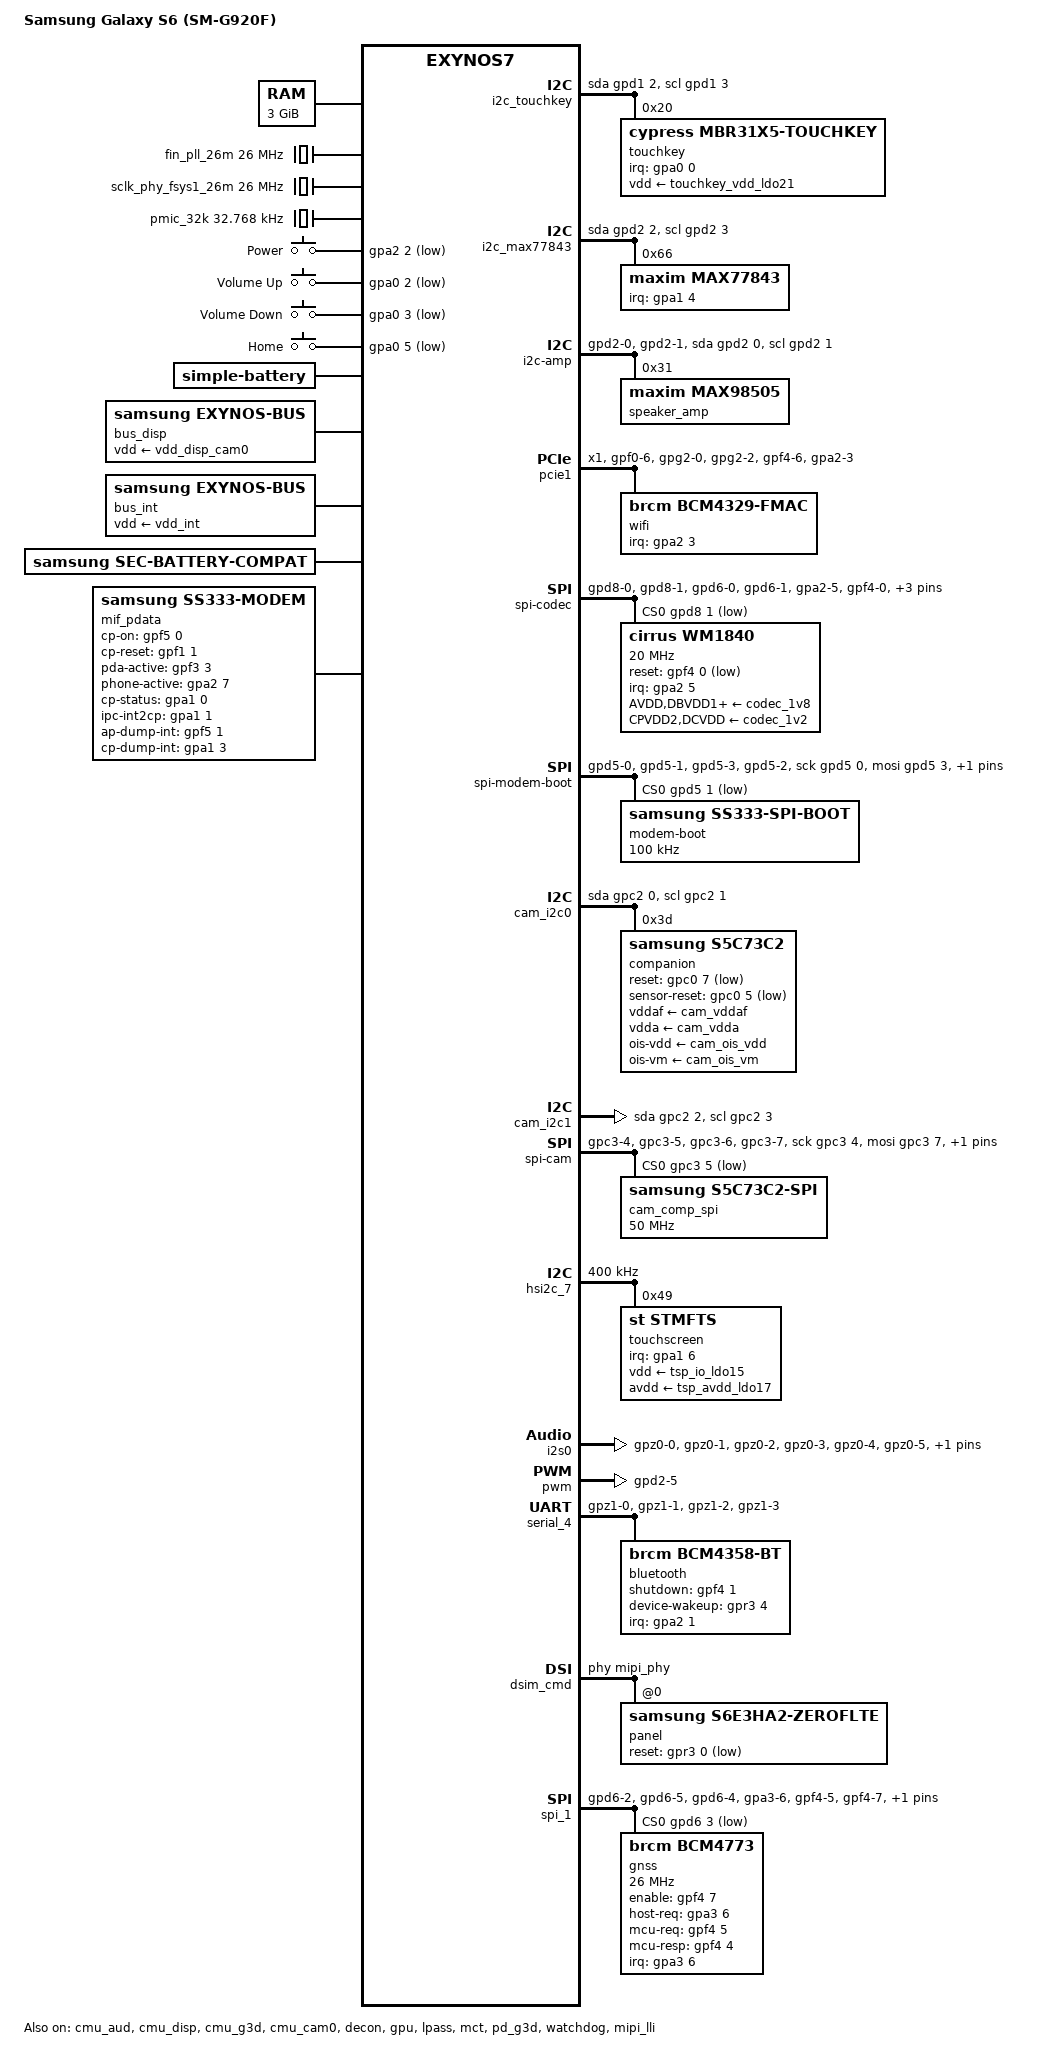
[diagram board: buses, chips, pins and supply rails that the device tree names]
// SPDX-License-Identifier: GPL-2.0
/*
 * Samsung Galaxy S6 (SM-G920F, zeroflte) device tree
 *
 * Exynos 7420, EUR single SIM, board revisions 00 to 07.
 * Hardware facts are taken from the stock 3.10 kernel (exynos7420.dtsi,
 * exynos7420-zero_common.dtsi, exynos7420-zeroflte_eur_open_*.dts).
 */

/dts-v1/;
#include "exynos7.dtsi"
#include <dt-bindings/gpio/gpio.h>
#include <dt-bindings/input/input.h>
#include <dt-bindings/interrupt-controller/irq.h>
#include <dt-bindings/leds/common.h>
#include <dt-bindings/sound/madera.h>
#include "exynos7420-zeroflte-touch-power.dtsi"

/ {
	model = "Samsung Galaxy S6 (SM-G920F)";
	compatible = "samsung,zeroflte", "samsung,exynos7420",
		     "samsung,exynos7";

	/*
	 * S-Boot picks the DTB from the DTBH table by these values. 10-11 is
	 * the EUR rev06 board range (androidboot.hw_rev=11), as in the 3.10
	 * exynos7420-zeroflte_eur_open_06.dts.
	 */
	model_info-chip = <7420>;
	model_info-platform = "android";
	model_info-subtype = "samsung";
	model_info-hw_rev = <10>;
	model_info-hw_rev_end = <11>;

	aliases {
		serial0 = &serial_4;
		/*
		 * Fixed i2c bus numbers, in the order they probe today. Android
		 * sepolicy and HALs name the bus directories (i2c-1 PMIC, i2c-3
		 * MAX77843), so the numbers must not follow probe order.
		 */
		i2c0 = &i2c_touchkey;
		i2c1 = "/i2c-tsp-main-pmic";
		i2c2 = "/i2c-tsp-analog-pmic";
		i2c3 = &i2c_max77843;
		i2c4 = "/i2c-amp";
		i2c5 = &hsi2c_7;
	};

	chosen {
		/*
		 * S-Boot writes bootargs and the initrd range here when it loads
		 * the boot image; the kernel's own arguments are in CONFIG_CMDLINE.
		 */
		#address-cells = <2>;
		#size-cells = <2>;
		ranges;

		/* Left running by S-Boot; DECON takes it over at bind. */
		framebuffer@e2a00000 {
			compatible = "simple-framebuffer";
			reg = <0x0 0xe2a00000 0x0 0x1000000>;
			width = <1440>;
			height = <2560>;
			stride = <(1440 * 4)>;
			format = "a8r8g8b8";
		};
	};

	memory@40000000 {
		device_type = "memory";
		reg = <0x0 0x40000000 0x0 0xc0000000>;
	};

	reserved-memory {
		#address-cells = <2>;
		#size-cells = <2>;
		ranges;

		/* S-Boot debug area */
		sec-debug@40000000 {
			reg = <0x0 0x40000000 0x0 0x10000>;
			no-map;
		};

		/* Exynos-snapshot header and kernel log ring, shared with the
		 * 3.10 kernels: init/dsh_esslog.c writes this boot's log there
		 * for TWRP's /proc/last_kmsg. */
		ess-header@46000000 {
			reg = <0x0 0x46000000 0x0 0x1000>;
			no-map;
		};

		ess-klog@46800000 {
			reg = <0x0 0x46800000 0x0 0x200000>;
			no-map;
		};

		ramoops@46d80000 {
			compatible = "ramoops";
			reg = <0x0 0x46d80000 0x0 0x80000>;
			record-size = <0x10000>;
			console-size = <0x40000>;
			pmsg-size = <0x20000>;
		};

		/* TIMA and AVC logs written by the secure world */
		tima@48002000 {
			reg = <0x0 0x48002000 0x0 0x200000>;
			no-map;
		};

		avc@48204000 {
			reg = <0x0 0x48204000 0x0 0x40000>;
			no-map;
		};

		/*
		 * DECON keeps scanning it out through its SysMMU until the
		 * first frame of its own: map it 1:1 and keep the DMA
		 * allocator off that IOVA range.
		 */
		boot_fb: framebuffer@e2a00000 {
			reg = <0x0 0xe2a00000 0x0 0x1000000>;
			iommu-addresses = <&decon 0xe2a00000 0x1000000>;
			no-map;
		};

		/* Secure world; stock /memreserve/ 0xfe800000 0x1800000 */
		trustzone@fe800000 {
			reg = <0x0 0xfe800000 0x0 0x1800000>;
			no-map;
		};
	};

	/*
	 * Fixed stand-ins for the CMU_TOP1 and PERIC outputs. Those CMUs are
	 * disabled below, so S-Boot's PLL and divider setup stays as is;
	 * the leaf CMUs find these parents by name. CMU_TOPC and CMU_TOP0
	 * are registered since the 2026-11-06 probe and supply the rest.
	 */
	clocks {
		aclk_fsys0_200: clock-aclk-fsys0-200 {
			compatible = "fixed-clock";
			#clock-cells = <0>;
			clock-frequency = <200000000>;
			clock-output-names = "aclk_fsys0_200";
		};

		sclk_mmc2: clock-sclk-mmc2 {
			compatible = "fixed-clock";
			#clock-cells = <0>;
			clock-frequency = <800000000>;
			clock-output-names = "sclk_mmc2";
		};

		sclk_usbdrd300: clock-sclk-usbdrd300 {
			compatible = "fixed-clock";
			#clock-cells = <0>;
			clock-frequency = <50000000>;
			clock-output-names = "sclk_usbdrd300";
		};

		aclk_fsys1_200: clock-aclk-fsys1-200 {
			compatible = "fixed-clock";
			#clock-cells = <0>;
			clock-frequency = <200000000>;
			clock-output-names = "aclk_fsys1_200";
		};

		sclk_mmc0: clock-sclk-mmc0 {
			compatible = "fixed-clock";
			#clock-cells = <0>;
			clock-frequency = <800000000>;
			clock-output-names = "sclk_mmc0";
		};

		sclk_mmc1: clock-sclk-mmc1 {
			compatible = "fixed-clock";
			#clock-cells = <0>;
			clock-frequency = <800000000>;
			clock-output-names = "sclk_mmc1";
		};

		sclk_ufsunipro20: clock-sclk-ufsunipro20 {
			compatible = "fixed-clock";
			#clock-cells = <0>;
			clock-frequency = <166666667>;
			clock-output-names = "sclk_ufsunipro20";
		};

		fin_pll_26m: clock-fin-pll-26m {
			compatible = "fixed-clock";
			#clock-cells = <0>;
			clock-frequency = <26000000>;
			clock-output-names = "fin_pll_26m";
		};

		sclk_phy_fsys1_26m: clock-sclk-phy-fsys1-26m {
			compatible = "fixed-clock";
			#clock-cells = <0>;
			clock-frequency = <26000000>;
			clock-output-names = "sclk_phy_fsys1_26m";
		};

		hsi2c7_clk: clock-hsi2c7 {
			compatible = "fixed-clock";
			#clock-cells = <0>;
			clock-frequency = <133000000>;
			clock-output-names = "hsi2c7_pclk";
		};

		/*
		 * 32.768 kHz from the S2MPS15 into WM1840 MCLK2. The vendor
		 * kernel (noble_arizona) uses it as the 32k and FLL reference
		 * and never gates it; mainline has no S2MPS15 clock driver, so
		 * it is fixed.
		 */
		pmic_32k: clock-pmic-32k {
			compatible = "fixed-clock";
			#clock-cells = <0>;
			clock-frequency = <32768>;
			clock-output-names = "pmic_32khz";
		};
	};

	/*
	 * Interrupt-driven: the alive-block EINTs work on this kernel (the
	 * touchkey IRQ on gpa0 fires). Power and Home wake the system.
	 */
	gpio-keys {
		compatible = "gpio-keys";
		pinctrl-names = "default";
		pinctrl-0 = <&key_power_pins &key_volup_pins &key_voldown_pins
			     &key_home_pins>;

		key-power {
			label = "Power";
			gpios = <&gpa2 2 GPIO_ACTIVE_LOW>;
			linux,code = <KEY_POWER>;
			wakeup-source;
		};

		key-volume-up {
			label = "Volume Up";
			gpios = <&gpa0 2 GPIO_ACTIVE_LOW>;
			linux,code = <KEY_VOLUMEUP>;
		};

		key-volume-down {
			label = "Volume Down";
			gpios = <&gpa0 3 GPIO_ACTIVE_LOW>;
			linux,code = <KEY_VOLUMEDOWN>;
		};

		key-home {
			label = "Home";
			gpios = <&gpa0 5 GPIO_ACTIVE_LOW>;
			linux,code = <KEY_HOMEPAGE>;
			wakeup-source;
		};
	};

	i2c_touchkey: i2c-touchkey {
		compatible = "i2c-gpio";
		sda-gpios = <&gpd1 2 (GPIO_ACTIVE_HIGH | GPIO_OPEN_DRAIN)>;
		scl-gpios = <&gpd1 3 (GPIO_ACTIVE_HIGH | GPIO_OPEN_DRAIN)>;
		i2c-gpio,delay-us = <2>;
		#address-cells = <1>;
		#size-cells = <0>;

		touchkey@20 {
			compatible = "cypress,mbr31x5-touchkey";
			reg = <0x20>;
			interrupt-parent = <&gpa0>;
			interrupts = <0 IRQ_TYPE_EDGE_FALLING>;
			pinctrl-names = "default";
			pinctrl-0 = <&touchkey_irq_pins>;
			linux,keycodes = <KEY_APPSELECT KEY_BACK>;
			vdd-supply = <&touchkey_vdd_ldo21>;
		};
	};

	/*
	 * Charging limits from the stock battery description, the same on
	 * every G920F revision (rev 06-07 boards: exynos7420-zeroflte_eur_
	 * battery_08/09.dtsi): float 4.35 V, fast charge 2 A, top-off
	 * 275 mA, recharge at 4.30 V. Charging stops below 0 degC and from
	 * 50 degC; below 10 degC and from 41 degC (battery swelling) the
	 * charger node's alert limits apply.
	 */
	battery: battery {
		compatible = "simple-battery";
		device-chemistry = "lithium-ion";
		constant-charge-voltage-max-microvolt = <4350000>;
		constant-charge-current-max-microamp = <2000000>;
		charge-term-current-microamp = <275000>;
		re-charge-voltage-microvolt = <4300000>;
		operating-range-celsius = <0 50>;
		alert-celsius = <10 41>;
	};

	/*
	 * Display bus (aclk_disp_400, CMU_TOP0). It has no load counters, so
	 * it runs at the lowest OPP the DECON's bandwidth request allows:
	 * 100 MHz while no frame is sent, up to 267 MHz, the stock cap, for
	 * two full-screen windows.
	 *
	 * Rates are divisions of the 800 MHz BUS0 PLL mux that S-Boot
	 * selects. 650 mV is the stock CAM/DISP ASV table v15 entry for
	 * 100-267 MHz at this chip's fused group (cam_disp_asv_group 0x999,
	 * ASV9, from the 3.10 boot log); stock ran these levels at that
	 * voltage, plus 37.5 mV only when the TMU reported the chip cold,
	 * which nothing here does. The upper limit of 1 V leaves room for the
	 * camera ISP, which shares BUCK5. G925F needs its own values.
	 */
	bus_disp: bus-disp {
		compatible = "samsung,exynos-bus";
		clocks = <&clock_top0 CLK_DOUT_ACLK_DISP_400>;
		clock-names = "bus";
		vdd-supply = <&vdd_disp_cam0>;
		operating-points-v2 = <&bus_disp_opp_table>;
		#interconnect-cells = <0>;
		/* display traffic also sets a DRAM floor */
		interconnects = <&dmc>;
	};

	bus_disp_opp_table: opp-table-bus-disp {
		compatible = "operating-points-v2";

		opp-100000000 {
			opp-hz = /bits/ 64 <100000000>;
			opp-microvolt = <650000 650000 1000000>;
		};
		opp-160000000 {
			opp-hz = /bits/ 64 <160000000>;
			opp-microvolt = <650000 650000 1000000>;
		};
		opp-200000000 {
			opp-hz = /bits/ 64 <200000000>;
			opp-microvolt = <650000 650000 1000000>;
		};
		opp-266666667 {
			opp-hz = /bits/ 64 <266666667>;
			opp-microvolt = <650000 650000 1000000>;
		};
	};

	/*
	 * Internal bus (INT, BUCK4), as on Exynos 5433 TM2: bus0 is the parent,
	 * driven by the general-port PPMUs of the four DREX channels (the
	 * non-CPU traffic; stock used the same counters for INT), and the other
	 * INT clocks follow it by OPP index.
	 *
	 * Every rate divides the 400 MHz bus0 PLL half that S-Boot selects
	 * (1600 MHz / 4); the muxes never change. 400 MHz is S-Boot's level and
	 * stock INT_LV7, 200 and 100 MHz are LV10 and LV11, with the same child
	 * clocks as stock. Voltages are the stock INT ASV table v15 entries for
	 * this chip's group (int_asv_group 0x999, ASV9): 712.5 mV for 400 MHz,
	 * 650 mV below. Stock's 532/560 MHz levels need 793.75 mV and another
	 * PLL; they are left out. MFC, MSCL, VPP and the other INT clocks keep
	 * their S-Boot rates. G925F needs its own values.
	 */
	bus_int: bus-int {
		compatible = "samsung,exynos-bus";
		clocks = <&clock_topc DOUT_ACLK_BUS0_532>;
		clock-names = "bus";
		devfreq-events = <&ppmu_event0_d0_general>,
				 <&ppmu_event0_d1_general>,
				 <&ppmu_event0_d2_general>,
				 <&ppmu_event0_d3_general>;
		vdd-supply = <&vdd_int>;
		exynos,saturation-ratio = <10>;
		operating-points-v2 = <&bus_int_opp_table>;
	};

	bus_int_opp_table: opp-table-bus-int {
		compatible = "operating-points-v2";

		opp-100000000 {
			opp-hz = /bits/ 64 <100000000>;
			opp-microvolt = <650000 650000 1000000>;
		};
		opp-200000000 {
			opp-hz = /bits/ 64 <200000000>;
			opp-microvolt = <650000 650000 1000000>;
		};
		opp-400000000 {
			opp-hz = /bits/ 64 <400000000>;
			opp-microvolt = <712500 712500 1000000>;
		};
	};

	bus_int_bus1: bus-int-bus1 {
		compatible = "samsung,exynos-bus";
		clocks = <&clock_topc DOUT_ACLK_BUS1_532>;
		clock-names = "bus";
		devfreq = <&bus_int>;
		operating-points-v2 = <&bus_int_bus1_opp_table>;
	};

	bus_int_bus1_opp_table: opp-table-bus-int-bus1 {
		compatible = "operating-points-v2";

		opp-100000000 {
			opp-hz = /bits/ 64 <100000000>;
		};
		opp-200000000 {
			opp-hz = /bits/ 64 <200000000>;
		};
		opp-400000000 {
			opp-hz = /bits/ 64 <400000000>;
		};
	};

	bus_int_bus1_200: bus-int-bus1-200 {
		compatible = "samsung,exynos-bus";
		clocks = <&clock_topc DOUT_ACLK_BUS1_200>;
		clock-names = "bus";
		devfreq = <&bus_int>;
		operating-points-v2 = <&bus_int_bus1_200_opp_table>;
	};

	bus_int_bus1_200_opp_table: opp-table-bus-int-bus1-200 {
		compatible = "operating-points-v2";

		opp-80000000 {
			opp-hz = /bits/ 64 <80000000>;
		};
		opp-100000000 {
			opp-hz = /bits/ 64 <100000000>;
		};
		opp-200000000 {
			opp-hz = /bits/ 64 <200000000>;
		};
	};

	bus_int_imem: bus-int-imem {
		compatible = "samsung,exynos-bus";
		clocks = <&clock_topc DOUT_ACLK_IMEM_266>;
		clock-names = "bus";
		devfreq = <&bus_int>;
		operating-points-v2 = <&bus_int_imem_opp_table>;
	};

	bus_int_imem_opp_table: opp-table-bus-int-imem {
		compatible = "operating-points-v2";

		opp-80000000 {
			opp-hz = /bits/ 64 <80000000>;
		};
		opp-100000000 {
			opp-hz = /bits/ 64 <100000000>;
		};
		opp-200000000 {
			opp-hz = /bits/ 64 <200000000>;
		};
	};

	bus_int_pclk: bus-int-pclk {
		compatible = "samsung,exynos-bus";
		clocks = <&clock_topc DOUT_PCLK_BUS01_133>;
		clock-names = "bus";
		devfreq = <&bus_int>;
		operating-points-v2 = <&bus_int_pclk_opp_table>;
	};

	bus_int_pclk_opp_table: opp-table-bus-int-pclk {
		compatible = "operating-points-v2";

		opp-25000000 {
			opp-hz = /bits/ 64 <25000000>;
		};
		opp-50000000 {
			opp-hz = /bits/ 64 <50000000>;
		};
		opp-100000000 {
			opp-hz = /bits/ 64 <100000000>;
		};
	};

	dmc_opp_table: opp-table-dmc {
		compatible = "operating-points-v2";
		opp-133000000 {
			opp-hz = /bits/ 64 <133000000>;
			opp-microvolt = <587500>;
		};
		opp-167000000 {
			opp-hz = /bits/ 64 <167000000>;
			opp-microvolt = <587500>;
		};
		opp-259000000 {
			opp-hz = /bits/ 64 <259000000>;
			opp-microvolt = <587500>;
		};
		opp-348000000 {
			opp-hz = /bits/ 64 <348000000>;
			opp-microvolt = <587500>;
		};
		opp-418000000 {
			opp-hz = /bits/ 64 <418000000>;
			opp-microvolt = <587500>;
		};
		opp-543000000 {
			opp-hz = /bits/ 64 <543000000>;
			opp-microvolt = <656250>;
		};
		opp-635000000 {
			opp-hz = /bits/ 64 <635000000>;
			opp-microvolt = <668750>;
		};
		opp-836000000 {
			opp-hz = /bits/ 64 <836000000>;
			opp-microvolt = <712500>;
		};
		opp-1026000000 {
			opp-hz = /bits/ 64 <1026000000>;
			opp-microvolt = <731250>;
		};
		opp-1264000000 {
			opp-hz = /bits/ 64 <1264000000>;
			opp-microvolt = <756250>;
		};
		opp-1464000000 {
			opp-hz = /bits/ 64 <1464000000>;
			opp-microvolt = <787500>;
		};
		opp-1552000000 {
			opp-hz = /bits/ 64 <1552000000>;
			opp-microvolt = <825000>;
			/* stock suspended on LV0 */
			opp-suspend;
		};
	};

	/* Bus for the MAX77843 MUIC/charger/fuel gauge (stock hsi2c_1 pins) */
	i2c_max77843: i2c-max77843 {
		compatible = "i2c-gpio";
		sda-gpios = <&gpd2 2 (GPIO_ACTIVE_HIGH | GPIO_OPEN_DRAIN)>;
		scl-gpios = <&gpd2 3 (GPIO_ACTIVE_HIGH | GPIO_OPEN_DRAIN)>;
		i2c-gpio,delay-us = <2>;
		#address-cells = <1>;
		#size-cells = <0>;

		/*
		 * TOPSYS: the MFD core. It creates the charger (0x69), fuel
		 * gauge (0x36) and MUIC (0x25) clients for its cells and carries
		 * the haptic block. INTB is level low and shared: each driver
		 * unmasks its block's source only once it handles it, and the
		 * fuel gauge, which is polled, stays masked.
		 */
		max77843: pmic@66 {
			compatible = "maxim,max77843";
			reg = <0x66>;
			interrupt-parent = <&gpa1>;
			interrupts = <4 IRQ_TYPE_LEVEL_LOW>;
			pinctrl-names = "default";
			pinctrl-0 = <&max77843_irq>;

			fuelgauge {
				compatible = "maxim,max77843-fuelgauge";
			};

			/*
			 * The input limit follows the charger type the MUIC
			 * detects. The alert limits are stock's swelling
			 * current and float voltage.
			 */
			charger {
				compatible = "maxim,max77843-charger";
				monitored-battery = <&battery>;
				extcon = <&muic>;
				maxim,alert-charge-current-microamp = <1100000>;
				maxim,alert-charge-voltage-microvolt = <4150000>;
			};

			/*
			 * MUIC: accessory detection and the micro-USB switch,
			 * which routes D+/D- to the USB PHY when a USB host or
			 * charger is attached and opens it on detach.
			 */
			muic: extcon {
				compatible = "maxim,max77843-muic";

				connector {
					compatible = "usb-b-connector";
					label = "micro-USB";
					type = "micro";
				};
			};

			/* LRA motor; the 3.10 G920F period is 33510 ns on PWM timer 1 */
			haptic {
				compatible = "maxim,max77843-haptic";
				haptic-supply = <&vcc_motor>;
				pwms = <&pwm 1 33510 0>;
				pwm-names = "haptic";
			};

			/*
			 * RGB indicator. R, G and B are channels 1-3; channel 0
			 * is not fitted on the S6. The full-scale codes are the
			 * 3.10 zeroflte calibration for the black panel
			 * (normal current 10 times br_ratio 450/200/500 %).
			 */
			led-controller {
				compatible = "maxim,max77843-led";

				multi-led {
					color = <LED_COLOR_ID_RGB>;
					function = LED_FUNCTION_STATUS;
					#address-cells = <1>;
					#size-cells = <0>;

					led@1 {
						reg = <1>;
						color = <LED_COLOR_ID_RED>;
						maxim,brt-code-max = <45>;
					};

					led@2 {
						reg = <2>;
						color = <LED_COLOR_ID_GREEN>;
						maxim,brt-code-max = <20>;
					};

					led@3 {
						reg = <3>;
						color = <LED_COLOR_ID_BLUE>;
						maxim,brt-code-max = <50>;
					};
				};
			};
		};
	};

	/*
	 * The loudspeaker amp sits on HSI2C0 (0x13640000). Its clock is in
	 * CMU_PERIC0, which this board leaves disabled, so the bus is
	 * bit-banged on the same pins, as for the MAX77843. The amp has no
	 * reset or enable line and no switched supply. Its IRQ (gpa2-0) is
	 * unused, as on stock.
	 */
	i2c-amp {
		compatible = "i2c-gpio";
		sda-gpios = <&gpd2 0 (GPIO_ACTIVE_HIGH | GPIO_OPEN_DRAIN)>;
		scl-gpios = <&gpd2 1 (GPIO_ACTIVE_HIGH | GPIO_OPEN_DRAIN)>;
		i2c-gpio,delay-us = <5>;
		i2c-gpio,timeout-ms = <100>;
		pinctrl-names = "default";
		pinctrl-0 = <&amp_i2c>;
		#address-cells = <1>;
		#size-cells = <0>;

		/*
		 * MAX98505, on the WM1840's AIF4. It returns voltage and
		 * current sense on its DOUT, in the stock slots.
		 */
		speaker_amp: audio-codec@31 {
			compatible = "maxim,max98505";
			reg = <0x31>;
			#sound-dai-cells = <0>;
			vmon-slot-no = <2>;
			imon-slot-no = <0>;
		};
	};

	/* PCIe channel 1, BCM4358 Wi-Fi */
	pcie1: pcie@157b0000 {
		compatible = "samsung,exynos7420-pcie";
		reg = <0x0 0x157b0000 0x0 0x1000>,
		      <0x0 0x15660000 0x0 0x1000>,
		      <0x0 0x15630000 0x0 0x1000>,
		      <0x0 0x1005265c 0x0 0x4>,
		      <0x0 0x105c071c 0x0 0x4>,
		      <0x0 0x156e0f00 0x0 0x4>,
		      <0x0 0x156f00e4 0x0 0x4>,
		      <0x0 0x156e0000 0x0 0xd00>,
		      <0x0 0x1c000000 0x0 0x1000>;
		reg-names = "dbi", "elbi", "phy", "block", "pmu", "cmu",
			    "phy_pcs", "gates", "config";
		interrupts = <GIC_SPI 205 IRQ_TYPE_LEVEL_HIGH>;
		#address-cells = <3>;
		#size-cells = <2>;
		device_type = "pci";
		ranges = <0x82000000 0x0 0x1c011000 0x0 0x1c011000 0x0 0x3feefff>;
		dma-ranges = <0x42000000 0x0 0x0 0x0 0x0 0x1 0x0>;
		bus-range = <0x00 0xff>;
		num-lanes = <1>;
		perst-gpios = <&gpg2 0 GPIO_ACTIVE_LOW>;
		wl-en-gpios = <&gpf4 6 GPIO_ACTIVE_HIGH>;
		pinctrl-names = "default", "pcie_reset";
		pinctrl-0 = <&pcie1_clkreq &pcie1_perst &pcie1_reset_clear
			     &cfg_wlanen &wlan_host_wake>;
		pinctrl-1 = <&pcie1_clkreq &pcie1_perst &pcie1_reset
			     &cfg_wlanen &wlan_host_wake>;

		/* Root port 00:00.0 */
		pcie@0,0 {
			device_type = "pci";
			reg = <0x0000 0x0 0x0 0x0 0x0>;
			#address-cells = <3>;
			#size-cells = <2>;
			ranges;

			/*
			 * BCM4358 at 01:00.0. brcmfmac arms WLAN_HOST_WAKE as
			 * its wake IRQ, so the link can stay associated while
			 * the host sleeps.
			 */
			wifi@0,0 {
				compatible = "brcm,bcm4329-fmac";
				reg = <0x10000 0x0 0x0 0x0 0x0>;
				interrupt-parent = <&gpa2>;
				interrupts = <3 IRQ_TYPE_EDGE_RISING>;
				interrupt-names = "host-wake";
				/*
				 * ISO 3166 to firmware ccode/rev, from Samsung's
				 * bcmdhd4358 translate_custom_table. Without it
				 * brcmfmac ignores the country Android sets on a
				 * BCM4358 and the firmware keeps its NVRAM default.
				 */
				brcm,ccode-map = "IR-XZ-11", "SD-XZ-11", "SY-XZ-11", "PS-XZ-11", "TL-XZ-11",
						"MH-XZ-11", "GL-GP-2", "AL-AL-2", "AS-AS-12", "AI-AI-1",
						"AF-AD-0", "AG-AG-2", "AM-AM-1", "AR-AU-6", "AW-AW-2",
						"AU-AU-6", "AT-AT-4", "AZ-AZ-2", "BS-BS-2", "BH-BH-4",
						"BD-BD-1", "BY-BY-3", "BE-BE-4", "BM-BM-12", "BA-BA-2",
						"BR-BR-2", "VG-VG-2", "BN-BN-4", "BG-BG-4", "KH-KH-2",
						"KY-KY-3", "CN-CN-38", "CO-CO-17", "CR-CR-17", "HR-HR-4",
						"CY-CY-4", "CZ-CZ-4", "DK-DK-4", "EE-EE-4", "ET-ET-2",
						"FI-FI-4", "FR-FR-5", "GF-GF-2", "DE-DE-7", "GR-GR-4",
						"GD-GD-2", "GP-GP-2", "GU-GU-30", "HK-HK-2", "HU-HU-4",
						"IS-IS-4", "IN-IN-3", "ID-ID-1", "IE-IE-5", "IL-IL-14",
						"IT-IT-4", "JP-JP-968", "JO-JO-3", "KE-SA-0", "KW-KW-5",
						"LA-LA-2", "LV-LV-4", "LB-LB-5", "LS-LS-2", "LI-LI-4",
						"LT-LT-4", "LU-LU-3", "MO-SG-0", "MK-MK-2", "MW-MW-1",
						"MY-MY-19", "DZ-DZ-2", "TW-TW-65", "MV-MV-3", "MT-MT-4",
						"MQ-MQ-2", "MR-MR-2", "MU-MU-2", "YT-YT-2", "MX-MX-44",
						"MD-MD-2", "MC-MC-1", "ME-ME-2", "MA-MA-2", "NL-NL-4",
						"AN-GD-2", "NZ-NZ-4", "NO-NO-4", "OM-OM-4", "PA-PA-17",
						"PG-AU-6", "PY-PY-2", "PE-PE-20", "PH-PH-5", "PL-PL-4",
						"PT-PT-4", "PR-PR-38", "RE-RE-2", "RO-RO-4", "SN-MA-2",
						"RS-RS-2", "SK-SK-4", "SI-SI-4", "ES-ES-4", "LK-LK-1",
						"SE-SE-4", "CH-CH-4", "TH-TH-5", "TT-TT-3", "TR-TR-7",
						"AE-AE-6", "GB-GB-6", "UY-VE-3", "VI-PR-38", "VA-VA-2",
						"VE-VE-3", "VN-VN-4", "ZM-LA-2", "EC-EC-21", "SV-SV-25",
						"KR-KR-70", "RU-RU-986", "UA-UA-16", "GT-GT-1", "MN-MN-1",
						"NI-NI-2", "UZ-MA-2", "ZA-ZA-19", "EG-EG-13", "TN-TN-1",
						"AO-AD-0", "BT-BJ-0", "BW-BJ-0", "LY-LI-4", "BO-NG-0",
						"UM-PR-38", "US-US-988", "CU-US-988", "CA-Q2-993";
			};
		};
	};

	sound {
		compatible = "samsung,zero-wm1840";
		model = "zero-wm1840";
		samsung,i2s-controller = <&i2s0>;
		samsung,speaker-amp = <&speaker_amp>;
		samsung,audio-routing =
			"HP", "HPOUT1L",
			"HP", "HPOUT1R",
			"RCV", "HPOUT3L",
			"RCV", "HPOUT3R",
			"SPK", "BE_OUT",
			"IN1ALN", "Main Mic",
			"IN1RN", "Main Mic",
			"Main Mic", "MICBIAS1",
			"IN2BLN", "Headset Mic",
			"IN2BLP", "Headset Mic",
			"Headset Mic", "MICBIAS2",
			"IN3LN", "Sub Mic",
			"IN3RN", "Sub Mic",
			"Sub Mic", "MICBIAS4",
			"DMICCLK4", "Third Mic",
			"DMICDAT4", "Third Mic",
			"Third Mic", "MICBIAS3";
	};

	/*
	 * Audio: Cirrus Logic WM1840 (Madera, CS47L85 family) on AIF1 <-> I2S0.
	 * Board facts are from the stock rev01-07 DT; only rev00 had a WM5110.
	 *
	 * The codec sits on SPI0's pins, but the SPI0 controller is clocked
	 * from CMU_PERIC1, which hangs the bus on this board, so the bus is
	 * bit-banged on the same pins in pinctrl_bus0 (CLK gpd8-0, CS gpd8-1,
	 * MISO gpd6-0, MOSI gpd6-1). IRQ is gpa2-5 (active low), reset gpf4-0.
	 *
	 * The codec's FLL1 runs from MCLK2, the PMIC's 32.768 kHz output,
	 * which S-Boot leaves running (the BCM4358 uses it too); pmic_32k
	 * stands in for it.
	 */
	spi-codec {
		compatible = "spi-gpio";
		#address-cells = <1>;
		#size-cells = <0>;
		sck-gpios = <&gpd8 0 GPIO_ACTIVE_HIGH>;
		miso-gpios = <&gpd6 0 GPIO_ACTIVE_HIGH>;
		mosi-gpios = <&gpd6 1 GPIO_ACTIVE_HIGH>;
		cs-gpios = <&gpd8 1 GPIO_ACTIVE_LOW>;
		num-chipselects = <1>;
		/*
		 * The SoC pins for the codec are set here: the codec node's
		 * own pinctrl-0 is taken by its internal pin-settings.
		 */
		pinctrl-names = "default";
		pinctrl-0 = <&codec_spi &codec_irq &codec_reset>;

		wm1840: codec@0 {
			compatible = "cirrus,wm1840";
			reg = <0>;
			spi-max-frequency = <20000000>;

			interrupt-parent = <&gpa2>;
			interrupts = <5 IRQ_TYPE_LEVEL_LOW>;
			interrupt-controller;
			#interrupt-cells = <2>;
			gpio-controller;
			#gpio-cells = <2>;
			reset-gpios = <&gpf4 0 GPIO_ACTIVE_LOW>;

			clocks = <&pmic_32k>;
			clock-names = "mclk2";

			AVDD-supply = <&codec_1v8>;
			DBVDD1-supply = <&codec_1v8>;
			DBVDD2-supply = <&codec_1v8>;
			DBVDD3-supply = <&codec_1v8>;
			DBVDD4-supply = <&codec_1v8>;
			CPVDD1-supply = <&codec_1v8>;
			CPVDD2-supply = <&codec_1v2>;
			DCVDD-supply = <&codec_1v2>;
			SPKVDDL-supply = <&codec_1v8>;
			SPKVDDR-supply = <&codec_1v8>;

			/*
			 * IN1 (main), IN3 (sub) and IN4 (third) are DMICs.
			 * cirrus,inmode only takes DIFF or SE: IN1 and IN3 are
			 * switched to DMIC with the "IN1 Mode"/"IN3 Mode"
			 * controls, IN4 is digital only. IN2B, the headset
			 * mic, is differential, the default.
			 */
			cirrus,dmic-ref = <MADERA_DMIC_REF_MICBIAS1
					   MADERA_DMIC_REF_MICBIAS2
					   MADERA_DMIC_REF_MICBIAS1
					   MADERA_DMIC_REF_MICVDD
					   MADERA_DMIC_REF_MICVDD
					   MADERA_DMIC_REF_MICVDD>;
			/* OUT2 and OUT3 (earpiece) are mono. */
			cirrus,out-mono = <0 1 1 0 0 0>;
			cirrus,max-channels-clocked = <2 0 0 0>;

			pinctrl-names = "default";
			pinctrl-0 = <&wm1840_pins>;

			wm1840_pins: pin-settings {
				aif1-pins {
					groups = "aif1";
					function = "aif1";
					bias-bus-hold;
				};

				aif2-pins {
					groups = "aif2";
					function = "aif2";
					bias-bus-hold;
				};

				aif3-pins {
					groups = "aif3";
					function = "aif3";
					bias-bus-hold;
				};

				aif4-pins {
					groups = "aif4";
					function = "aif4";
					bias-bus-hold;
				};
			};
		};
	};
};

/*
 * The clusters run from the alternate input while their PLL relocks. Its
 * BUS0_PLL side comes through CMU_TOPC. That was unreadable when this was
 * written and is registered now, but the 24 MHz oscillator stays the
 * alternate input: a known rate for the few tens of microseconds a relock
 * takes, independent of any TOPC setting.
 */
&clock_atlas {
	assigned-clocks = <&clock_atlas CLK_MOUT_BUS0_PLL_ATLAS_USER>;
	assigned-clock-parents = <&fin_pll>;
};

&clock_apollo {
	assigned-clocks = <&clock_apollo CLK_MOUT_BUS0_PLL_APOLLO_USER>;
	assigned-clock-parents = <&fin_pll>;
};

&cpu_atlas0 {
	cpu-supply = <&vdd_atlas>;
};

&cpu_atlas1 {
	cpu-supply = <&vdd_atlas>;
};

&cpu_atlas2 {
	cpu-supply = <&vdd_atlas>;
};

&cpu_atlas3 {
	cpu-supply = <&vdd_atlas>;
};

&cpu_apollo0 {
	cpu-supply = <&vdd_apollo>;
};

&cpu_apollo1 {
	cpu-supply = <&vdd_apollo>;
};

&cpu_apollo2 {
	cpu-supply = <&vdd_apollo>;
};

&cpu_apollo3 {
	cpu-supply = <&vdd_apollo>;
};

/* Leave the S-Boot root clock setup alone; see the stand-ins above. */
/*
 * CMU_TOPC and CMU_TOP0 are registered: every register their drivers use
 * reads and writes from Linux (2026-11-06 probe). Only undefined offsets
 * abort, such as TOP0 +0x0 and TOPC +0x80c; the early "TOP0 hangs" came
 * from a probe of TOP0's base. TOP1, CCORE, PERIC0 and PERIC1 stay off.
 */
&clock_top1 {
	status = "disabled";
};

&clock_ccore {
	status = "disabled";
};

&clock_peric0 {
	status = "disabled";
};

&clock_peric1 {
	status = "disabled";
};

&clock_fsys0 {
	clocks = <&fin_pll>, <&aclk_fsys0_200>, <&sclk_mmc2>;
};

&clock_fsys1 {
	/* fin_pll_26m stands in for dout_sclk_phy_fsys1 (not used by name). */
	clocks = <&fin_pll>, <&aclk_fsys1_200>, <&sclk_mmc0>, <&sclk_mmc1>,
		 <&sclk_ufsunipro20>, <&fin_pll_26m>, <&sclk_phy_fsys1_26m>;
};

&cmu_aud {
	status = "okay";
};

/*
 * CMU_DISP's parents come from CMU_TOP0 (aclk_disp_400, decon eclk and
 * vclk), which is registered, so the rates are the real S-Boot settings.
 */
&cmu_disp {
	status = "okay";
};

&cmu_g3d {
	status = "okay";
};

/*
 * CMU_CAM0 feeds the CSIS0 -> FIMC-BNS A (rear) and CSIS1 -> FIMC-BNS B
 * (front) capture paths. Its user muxes come up on OSCCLK with the power
 * domain; move them to the CMU_TOP0 bus clocks and the D-PHY byte clocks
 * (stock does the same when the ISP powers on, before any PHY runs), and
 * set the APB dividers to the stock sensor-on rates. The CMU_TOP0 parents
 * stay as S-Boot leaves them.
 */
&cmu_cam0 {
	assigned-clocks = <&cmu_cam0 CLK_MOUT_USER_ACLK_CAM0_CSIS0_690>,
			  <&cmu_cam0 CLK_MOUT_USER_ACLK_CAM0_BNSA_690>,
			  <&cmu_cam0 CLK_MOUT_USER_ACLK_CAM0_TREX_532>,
			  <&cmu_cam0 CLK_MOUT_USER_ACLK_CAM0_NOCP_133>,
			  <&cmu_cam0 CLK_MOUT_USER_ACLK_CAM0_CSIS1_174>,
			  <&cmu_cam0 CLK_MOUT_USER_ACLK_CAM0_BNSB_690>,
			  <&cmu_cam0 CLK_MOUT_USER_PHYCLK_RXBYTECLKHS0_S2A>,
			  <&cmu_cam0 CLK_MOUT_USER_PHYCLK_RXBYTECLKHS0_S4>,
			  <&cmu_cam0 CLK_MOUT_USER_PHYCLK_RXBYTECLKHS1_S4>,
			  <&cmu_cam0 CLK_MOUT_USER_PHYCLK_RXBYTECLKHS2_S4>,
			  <&cmu_cam0 CLK_MOUT_USER_PHYCLK_RXBYTECLKHS3_S4>,
			  <&cmu_cam0 CLK_DOUT_PCLK_CAM0_BNSA_345>,
			  <&cmu_cam0 CLK_DOUT_PCLK_CAM0_BNSB_345>,
			  <&cmu_cam0 CLK_DOUT_PCLK_CAM0_TREX_266>,
			  <&cmu_cam0 CLK_DOUT_PCLK_CAM0_TREX_133>;
	assigned-clock-parents = <&clock_top0 CLK_ACLK_CAM0_CSIS0_690>,
				 <&clock_top0 CLK_ACLK_CAM0_BNSA_690>,
				 <&clock_top0 CLK_ACLK_CAM0_TREX_532>,
				 <&clock_top0 CLK_ACLK_CAM0_NOCP_133>,
				 <&clock_top0 CLK_ACLK_CAM0_CSIS1_174>,
				 <&clock_top0 CLK_ACLK_CAM0_BNSB_690>,
				 <&cmu_cam0 CLK_PHY_RXBYTECLKHS0_S2A>,
				 <&cmu_cam0 CLK_PHY_RXBYTECLKHS0_S4>,
				 <&cmu_cam0 CLK_PHY_RXBYTECLKHS1_S4>,
				 <&cmu_cam0 CLK_PHY_RXBYTECLKHS2_S4>,
				 <&cmu_cam0 CLK_PHY_RXBYTECLKHS3_S4>;
	assigned-clock-rates = <0>, <0>, <0>, <0>, <0>, <0>,
			       <0>, <0>, <0>, <0>, <0>,
			       <330000000>, <330000000>, <266000000>,
			       <133000000>;
	status = "okay";
};

/*
 * The safe DRAM envelope from the CPU clock: stock's cpufreq bus tables
 * never ran MIF under 543 MHz with an A57 at 1 GHz or more or an A53 at
 * 700 MHz or more, and the deep levels under fast CPUs hang the SoC
 * (test-182/183/185). The OPP core sets this vote before the clock
 * rises, so it holds only that first step (543 MHz x 16 bytes); the
 * higher stock steps come from memlat in the dmc, for cores that wait on
 * DRAM. The vote changes only when a cluster crosses that clock.
 */
&cpu_atlas0 {
	interconnects = <&dmc &dmc>;
};

&cpu_atlas1 {
	interconnects = <&dmc &dmc>;
};

&cpu_atlas2 {
	interconnects = <&dmc &dmc>;
};

&cpu_atlas3 {
	interconnects = <&dmc &dmc>;
};

&cpu_apollo0 {
	interconnects = <&dmc &dmc>;
};

&cpu_apollo1 {
	interconnects = <&dmc &dmc>;
};

&cpu_apollo2 {
	interconnects = <&dmc &dmc>;
};

&cpu_apollo3 {
	interconnects = <&dmc &dmc>;
};

&cpu_atlas_opp_table {
	opp-800000000 {
		opp-peak-kBps = <0>;
	};
	opp-900000000 {
		opp-peak-kBps = <0>;
	};
	opp-1000000000 {
		opp-peak-kBps = <8688000>;
	};
	opp-1100000000 {
		opp-peak-kBps = <8688000>;
	};
	opp-1200000000 {
		opp-peak-kBps = <8688000>;
	};
	opp-1300000000 {
		opp-peak-kBps = <8688000>;
	};
	opp-1400000000 {
		opp-peak-kBps = <8688000>;
	};
	opp-1500000000 {
		opp-peak-kBps = <8688000>;
	};
	opp-1600000000 {
		opp-peak-kBps = <8688000>;
	};
	opp-1704000000 {
		opp-peak-kBps = <8688000>;
	};
	opp-1800000000 {
		opp-peak-kBps = <8688000>;
	};
};

&cpu_apollo_opp_table {
	opp-400000000 {
		opp-peak-kBps = <0>;
	};
	opp-500000000 {
		opp-peak-kBps = <0>;
	};
	opp-600000000 {
		opp-peak-kBps = <0>;
	};
	opp-700000000 {
		opp-peak-kBps = <8688000>;
	};
	opp-800000000 {
		opp-peak-kBps = <8688000>;
	};
	opp-900000000 {
		opp-peak-kBps = <8688000>;
	};
	opp-1000000000 {
		opp-peak-kBps = <8688000>;
	};
	opp-1104000000 {
		opp-peak-kBps = <8688000>;
	};
	opp-1200000000 {
		opp-peak-kBps = <8688000>;
	};
	opp-1296000000 {
		opp-peak-kBps = <8688000>;
	};
	opp-1400000000 {
		opp-peak-kBps = <8688000>;
	};
	opp-1500000000 {
		opp-peak-kBps = <8688000>;
	};
};

&decon {
	status = "okay";
	interconnects = <&bus_disp &dmc>;
	/*
	 * Only S-Boot sets up the DSI link and panel; keep the display
	 * running through system sleep.
	 */
	samsung,bootloader-display;
	samsung,disp-sysreg = <&sysreg_system_controller>;
	memory-region = <&boot_fb>;

	/*
	 * The panel's tearing-effect output on GPG0-0, an EINT (3.10:
	 * decon_fb gpios = <&gpg0 0 0xf>, used to time each frame's
	 * software trigger). DECON sends every frame at a TE edge.
	 */
	te-gpios = <&gpg0 0 GPIO_ACTIVE_HIGH>;

	/* Command-mode (i80) MIPI panel, S6E3HA2 */
	i80-if-timings {
	};

	display-timings {
		native-mode = <&decon_timing0>;

		decon_timing0: timing-0 {
			clock-frequency = <221042000>;
			hactive = <1440>;
			vactive = <2560>;
			hfront-porch = <1>;
			hback-porch = <1>;
			hsync-len = <1>;
			vfront-porch = <1>;
			vback-porch = <15>;
			vsync-len = <1>;
		};
	};
};

&fin_pll {
	clock-frequency = <24000000>;
};

&gpu {
	status = "okay";

	/*
	 * The GPU is not attached to pd_g3d. pd_g3d stays powered on its
	 * own: its samsung,exynos7420-g3d-pd compatible makes
	 * exynos-pm-domains set GENPD_FLAG_ALWAYS_ON, and pd_ignore_unused
	 * on the cmdline keeps unused domains on as well. The generic 5433
	 * power-on sequence cannot bring G3D back (the vendor sequence also
	 * writes CMU_TOP registers that hang this board), so the domain
	 * must never power off.
	 *
	 * History: with power-domains attached and no always-on flag,
	 * panfrost's 50 ms autosuspend let genpd power pd_g3d off; the next
	 * runtime resume read 0x14AC0000 and took an asynchronous SError
	 * (p207). With the always-on flag, keeping the property should be
	 * safe too (the p211 plan), but the board runs without it (the p210
	 * fallback) and no p211 boot is recorded. Panfrost runtime PM only
	 * powers the GPU cores on and off.
	 */
	/delete-property/ power-domains;

	/*
	 * GPU DVFS through panfrost devfreq (simple_ondemand). Levels are
	 * the 3.10 G3D_PLL table up to its 700 MHz limit
	 * (GPU_MAX_CLOCK_LIMIT); 772 MHz is left out until 700 MHz has run
	 * stable. Voltages are the ASV group 0 (worst chip) column of the
	 * 3.10 G3D ASV tables v12/v15, so they hold for any ASV group.
	 */
	mali-supply = <&vdd_g3d>;
	operating-points-v2 = <&gpu_opp_table>;

	gpu_opp_table: opp-table {
		compatible = "operating-points-v2";

		opp-266000000 {
			opp-hz = /bits/ 64 <266000000>;
			opp-microvolt = <762500>;
		};

		opp-350000000 {
			opp-hz = /bits/ 64 <350000000>;
			opp-microvolt = <768750>;
		};

		opp-420000000 {
			opp-hz = /bits/ 64 <420000000>;
			opp-microvolt = <775000>;
		};

		opp-544000000 {
			opp-hz = /bits/ 64 <544000000>;
			opp-microvolt = <812500>;
		};

		opp-600000000 {
			opp-hz = /bits/ 64 <600000000>;
			opp-microvolt = <850000>;
		};

		opp-700000000 {
			opp-hz = /bits/ 64 <700000000>;
			opp-microvolt = <893750>;
		};
	};
};

&hsi2c_7 {
	/* PCLK_HSI2C7 lives in the disabled CMU_PERIC1; S-Boot leaves it on. */
	clocks = <&hsi2c7_clk>;
	/delete-property/ pinctrl-names;
	/delete-property/ pinctrl-0;
	clock-frequency = <400000>;
	status = "okay";

	touchscreen@49 {
		compatible = "st,stmfts";
		reg = <0x49>;
		interrupt-parent = <&gpa1>;
		interrupts = <6 IRQ_TYPE_LEVEL_LOW>;
		pinctrl-names = "default";
		pinctrl-0 = <&tsp_attn_pin>;
		vdd-supply = <&tsp_io_ldo15>;
		avdd-supply = <&tsp_avdd_ldo17>;
		touchscreen-size-x = <4096>;
		touchscreen-size-y = <4096>;
		st,int-enable-reg;
	};
};

&i2s0 {
	pinctrl-names = "default";
	pinctrl-0 = <&i2s0_bus>;
	status = "okay";
};

&lpass {
	status = "okay";
};

&mct {
	status = "okay";
};

&pd_g3d {
	status = "okay";
};

&pinctrl_alive {
	key_power_pins: key-power-pins {
		samsung,pins = "gpa2-2";
		samsung,pin-function = <EXYNOS_PIN_FUNC_EINT>;
		samsung,pin-pud = <EXYNOS_PIN_PULL_UP>;
	};

	key_volup_pins: key-volup-pins {
		samsung,pins = "gpa0-2";
		samsung,pin-function = <EXYNOS_PIN_FUNC_EINT>;
		samsung,pin-pud = <EXYNOS_PIN_PULL_UP>;
	};

	key_voldown_pins: key-voldown-pins {
		samsung,pins = "gpa0-3";
		samsung,pin-function = <EXYNOS_PIN_FUNC_EINT>;
		samsung,pin-pud = <EXYNOS_PIN_PULL_UP>;
	};

	key_home_pins: key-home-pins {
		samsung,pins = "gpa0-5";
		samsung,pin-function = <EXYNOS_PIN_FUNC_EINT>;
		samsung,pin-pud = <EXYNOS_PIN_PULL_UP>;
	};

	/*
	 * The touchkey INT output is open-drain. Without the pull-up the
	 * line stays low after the first event and no later edge fires.
	 */
	touchkey_irq_pins: touchkey-irq-pins {
		samsung,pins = "gpa0-0";
		samsung,pin-function = <EXYNOS_PIN_FUNC_EINT>;
		samsung,pin-pud = <EXYNOS_PIN_PULL_UP>;
	};

	tsp_attn_pin: tsp-attn-pins {
		samsung,pins = "gpa1-6";
		samsung,pin-function = <EXYNOS_PIN_FUNC_EINT>;
		samsung,pin-pud = <EXYNOS_PIN_PULL_NONE>;
	};

	bt_host_wake: bt-host-wake-pins {
		samsung,pins = "gpa2-1";
		samsung,pin-function = <EXYNOS_PIN_FUNC_EINT>;
		samsung,pin-pud = <EXYNOS_PIN_PULL_NONE>;
	};

	/* MAX77843 INTB: open drain, active low (3.10 irq-gpio gpa1-4) */
	max77843_irq: max77843-irq {
		samsung,pins = "gpa1-4";
		samsung,pin-function = <EXYNOS_PIN_FUNC_EINT>;
		samsung,pin-pud = <EXYNOS_PIN_PULL_UP>;
	};

	pmic_irq: pmic-irq {
		samsung,pins = "gpa3-7";
		samsung,pin-function = <EXYNOS_PIN_FUNC_EINT>;
		samsung,pin-pud = <EXYNOS_PIN_PULL_UP>;
	};

	/* Active high, driven by the BCM4358; pulled down as in the stock tree */
	wlan_host_wake: wlan-host-wake-pins {
		samsung,pins = "gpa2-3";
		samsung,pin-function = <EXYNOS_PIN_FUNC_EINT>;
		samsung,pin-pud = <EXYNOS_PIN_PULL_DOWN>;
	};

	/* WM1840 IRQ, active low */
	codec_irq: codec-irq-pins {
		samsung,pins = "gpa2-5";
		samsung,pin-function = <EXYNOS_PIN_FUNC_EINT>;
		samsung,pin-pud = <EXYNOS_PIN_PULL_NONE>;
	};
};

&pinctrl_aud {
	bt_uart_bus: bt-uart-bus-pins {
		samsung,pins = "gpz1-0", "gpz1-1", "gpz1-2", "gpz1-3";
		samsung,pin-function = <EXYNOS_PIN_FUNC_2>;
		samsung,pin-pud = <EXYNOS_PIN_PULL_UP>;
	};

	i2s0_bus: i2s0-bus-pins {
		samsung,pins = "gpz0-0", "gpz0-1", "gpz0-2", "gpz0-3",
			       "gpz0-4", "gpz0-5", "gpz0-6";
		samsung,pin-function = <EXYNOS_PIN_FUNC_2>;
		samsung,pin-pud = <EXYNOS_PIN_PULL_DOWN>;
		samsung,pin-drv = <EXYNOS7_PIN_DRV_LV1>;
	};
};

&pinctrl_bus0 {
	pwm_tout1: pwm-tout1-pins {
		samsung,pins = "gpd2-5";
		samsung,pin-function = <EXYNOS_PIN_FUNC_2>;
		samsung,pin-pud = <EXYNOS_PIN_PULL_NONE>;
	};

	/* WM1840 bit-banged SPI: CLK gpd8-0, CS gpd8-1, MISO gpd6-0, MOSI gpd6-1 */
	codec_spi: codec-spi-pins {
		samsung,pins = "gpd8-0", "gpd8-1", "gpd6-0", "gpd6-1";
		samsung,pin-pud = <EXYNOS_PIN_PULL_NONE>;
		samsung,pin-drv = <EXYNOS7_PIN_DRV_LV1>;
	};

	/* HSI2C0 pins, bit-banged; pulls off, as on stock. */
	amp_i2c: amp-i2c-pins {
		samsung,pins = "gpd2-0", "gpd2-1";
		samsung,pin-function = <EXYNOS_PIN_FUNC_INPUT>;
		samsung,pin-pud = <EXYNOS_PIN_PULL_NONE>;
	};
};

&pinctrl_bus1 {
	/*
	 * DISPLAY_1.6V_EN, the panel rail enable S-Boot sets: held through
	 * sleep like the panel reset. Stock drove it low there because it
	 * switched the panel off with the screen.
	 */
	panel_pwr_sleep: panel-pwr-sleep-pins {
		samsung,pins = "gpf4-3";
		samsung,pin-con-pdn = <EXYNOS_PIN_PDN_PREV>;
		samsung,pin-pud-pdn = <EXYNOS_PIN_PULL_NONE>;
	};

	bt_en_pin: bt-en-pins {
		samsung,pins = "gpf4-1";
		samsung,pin-function = <EXYNOS_PIN_FUNC_OUTPUT>;
		samsung,pin-pud = <EXYNOS_PIN_PULL_NONE>;
	};

	/* The PCIe pins keep their state through sleep, as on the stock kernel */
	pcie1_clkreq: pcie1-clkreq-pins {
		samsung,pins = "gpf0-6";
		samsung,pin-function = <EXYNOS_PIN_FUNC_2>;
		samsung,pin-pud = <EXYNOS_PIN_PULL_NONE>;
		samsung,pin-drv = <EXYNOS7_PIN_DRV_LV4>;
		samsung,pin-con-pdn = <EXYNOS_PIN_PDN_PREV>;
		samsung,pin-pud-pdn = <EXYNOS_PIN_PULL_NONE>;
	};

	pcie1_perst: pcie1-perst-pins {
		samsung,pins = "gpg2-0";
		samsung,pin-function = <EXYNOS_PIN_FUNC_OUTPUT>;
		samsung,pin-pud = <EXYNOS_PIN_PULL_NONE>;
		samsung,pin-drv = <EXYNOS7_PIN_DRV_LV4>;
		samsung,pin-con-pdn = <EXYNOS_PIN_PDN_PREV>;
	};

	/*
	 * WAKE# pull states: pulled up normally, pulled down for the short
	 * link reset pulse the driver gives before training the link again.
	 */
	pcie1_reset_clear: pcie1-reset-clear-pins {
		samsung,pins = "gpg2-2";
		samsung,pin-function = <EXYNOS_PIN_FUNC_2>;
		samsung,pin-pud = <EXYNOS_PIN_PULL_UP>;
		samsung,pin-con-pdn = <EXYNOS_PIN_PDN_PREV>;
		samsung,pin-pud-pdn = <EXYNOS_PIN_PULL_UP>;
	};

	pcie1_reset: pcie1-reset-pins {
		samsung,pins = "gpg2-2";
		samsung,pin-function = <EXYNOS_PIN_FUNC_2>;
		samsung,pin-pud = <EXYNOS_PIN_PULL_DOWN>;
		samsung,pin-con-pdn = <EXYNOS_PIN_PDN_PREV>;
		samsung,pin-pud-pdn = <EXYNOS_PIN_PULL_DOWN>;
	};

	cfg_wlanen: cfg-wlanen-pins {
		samsung,pins = "gpf4-6";
		samsung,pin-function = <EXYNOS_PIN_FUNC_OUTPUT>;
		samsung,pin-pud = <EXYNOS_PIN_PULL_NONE>;
		samsung,pin-drv = <EXYNOS7_PIN_DRV_LV4>;
		samsung,pin-con-pdn = <EXYNOS_PIN_PDN_PREV>;
	};

	/* WM1840 reset */
	codec_reset: codec-reset-pins {
		samsung,pins = "gpf4-0";
		samsung,pin-function = <EXYNOS_PIN_FUNC_OUTPUT>;
		samsung,pin-pud = <EXYNOS_PIN_PULL_DOWN>;
	};
};

/*
 * The secure world owns the four pin controllers on the PERIC1 side, as
 * the stock kernel's CONFIG_ESE_SECURE_GPIO, CONFIG_SENSORS_FP_SPI_GPIO
 * and CONFIG_MST_SECURE_GPIO record:
 *   pinctrl_nfc   14cd0000  gpj0  HRM I2C, MST
 *   pinctrl_touch 14ce0000  gpj1  touch I2C, MST
 *   pinctrl_ff    14c90000  gpg4  eSE SPI
 *   pinctrl_ese   14ca0000  gpv7  fingerprint SPI
 * Normal-world reads of them abort. Probe does not touch the registers,
 * but saving them at suspend_late does, so Linux must not instantiate
 * them. Pins on them stay as the bootloader muxed them.
 */
&pinctrl_nfc {
	status = "disabled";
};

&pinctrl_touch {
	status = "disabled";
};

&pinctrl_ff {
	status = "disabled";
};

&pinctrl_ese {
	status = "disabled";
};

&pinctrl_fsys1 {
	bt_wake_pin: bt-wake-pins {
		samsung,pins = "gpr3-4";
		samsung,pin-function = <EXYNOS_PIN_FUNC_OUTPUT>;
		samsung,pin-pud = <EXYNOS_PIN_PULL_NONE>;
	};

	/*
	 * Panel reset: held through sleep. Left to the power-down default,
	 * the panel came back from a deep sleep reset, under a display that
	 * stays set up.
	 */
	panel_rst_sleep: panel-rst-sleep-pins {
		samsung,pins = "gpr3-0";
		samsung,pin-con-pdn = <EXYNOS_PIN_PDN_PREV>;
		samsung,pin-pud-pdn = <EXYNOS_PIN_PULL_NONE>;
	};
};

/* Bluetooth UART (BCM4358) */
/*
 * Tell S-Boot the restart target the way Samsung's 3.10 sec_reboot does:
 * it reads the target from PMU INFORM3 (0x12345670 | mode) and skips the
 * charger screen when INFORM2 holds 0x12345678. exynos-syscon-restart.dtsi
 * already resets through PMU SWRESET.
 */
&pmu_system_controller {
	reboot-mode-target {
		compatible = "syscon-reboot-mode";
		offset = <0x80c>;
		mode-normal = <0x12345670>;
		mode-bootloader = <0x12345671>;
		mode-download = <0x12345671>;
		mode-recovery = <0x12345674>;
	};

	reboot-mode-no-lpm {
		compatible = "syscon-reboot-mode";
		offset = <0x808>;
		mode-normal = <0x12345678>;
		mode-bootloader = <0x12345678>;
		mode-download = <0x12345678>;
		mode-recovery = <0x12345678>;
	};
};

/*
 * PWM timers, for the haptic motor (TOUT1 on gpd2-5, 3.10 vibetonz_pwm).
 * PCLK_PWM is a CMU_PERIC0 gate, and CMU_PERIC0 is disabled here, so a
 * fixed clock stands in at the aclk_peric0_66 rate; the gate itself is
 * left as S-Boot set it.
 */
/ {
	pwm_pclk: clock-pwm {
		compatible = "fixed-clock";
		#clock-cells = <0>;
		clock-frequency = <66000000>;
		clock-output-names = "pclk_pwm";
	};
};

&pwm {
	clocks = <&pwm_pclk>;
	clock-names = "timers";
	pinctrl-names = "default";
	pinctrl-0 = <&pwm_tout1>;
	status = "okay";
};

/*
 * BCM4358 Bluetooth on UART4 through the serdev hci_bcm driver. 6.6
 * serial_core registers every samsung_tty port as a serdev controller, so
 * the child below binds hci_bcm directly; no btattach is needed.
 *
 * Hardware facts from the stock SMG920FXXS6ETK DT and bcm4358.c:
 *   BT_EN gpf4-1, BT_WAKE gpr3-4, BT_HOST_WAKE gpa2-1, all active high
 *   (the stock LPM driver drives BT_WAKE 1 to wake the chip and treats
 *   host-wake 1 as "chip has data"). gpz1-0..3 carry RXD/TXD/CTS/RTS.
 *   The 32 kHz LPO is the S2MPS15 BT_EN32KHZ output, which the bootloader
 *   leaves on and the stock kernel never touches, so no clock is listed.
 *   The stock libbt ran the link at 921600 (libbt_vndcfg.txt).
 * "brcm,bcm4358-bt" is matched by hci_bcm with the BCM43540 (4354-family)
 * device data.
 */
&serial_4 {
	pinctrl-names = "default";
	pinctrl-0 = <&bt_uart_bus>;
	status = "okay";

	bluetooth {
		compatible = "brcm,bcm4358-bt";
		pinctrl-names = "default";
		pinctrl-0 = <&bt_en_pin &bt_wake_pin &bt_host_wake>;
		shutdown-gpios = <&gpf4 1 GPIO_ACTIVE_HIGH>;
		device-wakeup-gpios = <&gpr3 4 GPIO_ACTIVE_HIGH>;
		interrupt-parent = <&gpa2>;
		interrupts = <1 IRQ_TYPE_EDGE_RISING>;
		interrupt-names = "host-wakeup";
		max-speed = <921600>;
	};
};

/*
 * DSIM0 as S-Boot left it (4 lanes, command mode, MIC), for panel
 * commands only. The panel driver's backlight sends the brightness
 * (gamma, AOR, ELVSS, VINT) through it. With the zeroflte compatible
 * the value is the luminance in cd/m2, 2 to 360, set from the stock S6
 * tables. Panel reset is gpr3-0, active low
 * (3.10: dsim gpios = <&gpr3 0 0x1>); S-Boot also sets the panel
 * rail enable gpf4-3 (DISPLAY_1.6V_EN). Both keep their level in sleep. The
 * supplies (S2MPB02 LDO16 VCC_3.0V_LCD, VCC_DISPLAY_1.8V) stay as S-Boot
 * set them and are not described here, so Linux never switches them.
 * After deep sleep the driver rebuilds the link from S-Boot's setup; the
 * D-PHY is taken for its reset.
 * If a test hangs the display, set status = "disabled" (or boot with
 * exynos7420_dsim_cmd.enable=0) and the link is left alone.
 */
&soc {
	dsim_cmd: dsi@13900000 {
		compatible = "samsung,exynos7420-dsim-cmd";
		reg = <0x13900000 0x1000>;
		clocks = <&cmu_disp CLK_PCLK_DSIM0>;
		clock-names = "pclk";
		phys = <&mipi_phy 1>;
		phy-names = "dsim";
		status = "okay";
		#address-cells = <1>;
		#size-cells = <0>;

		panel@0 {
			compatible = "samsung,s6e3ha2-zeroflte", "samsung,s6e3ha2";
			reg = <0>;
			reset-gpios = <&gpr3 0 GPIO_ACTIVE_LOW>;
			pinctrl-names = "default";
			pinctrl-0 = <&panel_rst_sleep &panel_pwr_sleep>;
		};
	};

	/* INT bus load: general-port PPMUs of the four DREX channels */
	ppmu_d0_general: ppmu@10830000 {
		compatible = "samsung,exynos-ppmu-v2";
		reg = <0x10830000 0x300>;

		events {
			ppmu_event0_d0_general: ppmu-event0-d0-general {
				event-name = "ppmu-event0-d0-general";
			};
		};
	};

	ppmu_d1_general: ppmu@10930000 {
		compatible = "samsung,exynos-ppmu-v2";
		reg = <0x10930000 0x300>;

		events {
			ppmu_event0_d1_general: ppmu-event0-d1-general {
				event-name = "ppmu-event0-d1-general";
			};
		};
	};

	ppmu_d2_general: ppmu@10a30000 {
		compatible = "samsung,exynos-ppmu-v2";
		reg = <0x10a30000 0x300>;

		events {
			ppmu_event0_d2_general: ppmu-event0-d2-general {
				event-name = "ppmu-event0-d2-general";
			};
		};
	};

	ppmu_d3_general: ppmu@10b30000 {
		compatible = "samsung,exynos-ppmu-v2";
		reg = <0x10b30000 0x300>;

		events {
			ppmu_event0_d3_general: ppmu-event0-d3-general {
				event-name = "ppmu-event0-d3-general";
			};
		};
	};

	ppmu_d0_cpu: ppmu@10860000 {
		compatible = "samsung,exynos-ppmu-v2";
		reg = <0x10860000 0x300>;

		events {
			ppmu_event0_d0_cpu: ppmu-event0-d0-cpu {
				event-name = "ppmu-event0-d0-cpu";
			};
		};
	};

	ppmu_d1_cpu: ppmu@10960000 {
		compatible = "samsung,exynos-ppmu-v2";
		reg = <0x10960000 0x300>;

		events {
			ppmu_event0_d1_cpu: ppmu-event0-d1-cpu {
				event-name = "ppmu-event0-d1-cpu";
			};
		};
	};

	ppmu_d2_cpu: ppmu@10a60000 {
		compatible = "samsung,exynos-ppmu-v2";
		reg = <0x10a60000 0x300>;

		events {
			ppmu_event0_d2_cpu: ppmu-event0-d2-cpu {
				event-name = "ppmu-event0-d2-cpu";
			};
		};
	};

	ppmu_d3_cpu: ppmu@10b60000 {
		compatible = "samsung,exynos-ppmu-v2";
		reg = <0x10b60000 0x300>;

		events {
			ppmu_event0_d3_cpu: ppmu-event0-d3-cpu {
				event-name = "ppmu-event0-d3-cpu";
			};
		};
	};

	/*
	 * DRAM controller: per channel the DREX, its LPDDR4 PHY, VT monitor
	 * and CMU_MIF, plus the MIF PLL muxes in CMU_TOPC. OPPs are the DRAM
	 * clock; voltages are the stock MIF ASV table v15 entries for this
	 * chip's group (ASV9). G925F needs its own values. The driver's
	 * lowest level is LV9 (259 MHz), stock's default MIF QoS; LV10 and
	 * LV11 stay listed for experiments (min_khz). Stock LV12 (100 MHz)
	 * is left out: switching LV11 -> LV12 hangs this phone (test-79,
	 * twice), and LV11 is 133 MHz at the same voltage.
	 */
	dmc: memory-controller@10800000 {
		compatible = "samsung,exynos7420-dmc";
		reg = <0x10800000 0x1000>, <0x10900000 0x1000>,
		      <0x10a00000 0x1000>, <0x10b00000 0x1000>,
		      <0x10820000 0x1000>, <0x10920000 0x1000>,
		      <0x10a20000 0x1000>, <0x10b20000 0x1000>,
		      <0x10890000 0x100>, <0x10990000 0x100>,
		      <0x10a90000 0x100>, <0x10b90000 0x100>,
		      <0x10850000 0x2000>, <0x10950000 0x2000>,
		      <0x10a50000 0x2000>, <0x10b50000 0x2000>,
		      <0x10570000 0x2000>;
		reg-names = "drex0", "drex1", "drex2", "drex3",
			    "phy0", "phy1", "phy2", "phy3",
			    "vtmon0", "vtmon1", "vtmon2", "vtmon3",
			    "cmu-mif0", "cmu-mif1", "cmu-mif2", "cmu-mif3",
			    "cmu-topc";
		clocks = <&clock_topc FOUT_MIF_PLL>,
			 <&clock_topc MOUT_ACLK_MIF_PLL>,
			 <&clock_topc SCLK_BUS0_PLL_MIF>,
			 <&clock_topc MOUT_SCLK_BUS0_PLL_MIF>,
			 <&clock_topc DOUT_SCLK_BUS0_PLL_MIF>,
			 <&clock_topc MOUT_ACLK_CCORE_532>,
			 <&clock_topc DOUT_ACLK_CCORE_532>,
			 <&clock_topc DOUT_ACLK_CCORE_133>;
		clock-names = "fout_mif_pll", "mout_aclk_mif_pll",
			      "sclk_bus0_pll_mif", "mout_sclk_bus0_pll_mif",
			      "dout_sclk_bus0_pll_mif", "mout_aclk_ccore_532",
			      "dout_aclk_ccore_532", "dout_aclk_ccore_133";
		vdd-supply = <&vdd_mif>;
		operating-points-v2 = <&dmc_opp_table>;
		/*
		 * DRAM floor per GPU clock (GPU kHz, MIF kHz) from the stock
		 * 3.10 G3D DVFS table; the driver follows the GPU devfreq.
		 * The idle GPU stays at 266 MHz, so that level holds no
		 * floor: the stock 3.10 vote went away with the GPU power.
		 */
		samsung,gpu = <&gpu>;
		samsung,gpu-mif-floors = <350000 543000>,
					 <420000 1026000>, <544000 1026000>,
					 <600000 1552000>, <700000 1552000>;
		/*
		 * Load: the CPU and general ports of each channel (the
		 * general ones are shared with bus_int).
		 */
		devfreq-events = <&ppmu_event0_d0_cpu>, <&ppmu_event0_d1_cpu>,
				 <&ppmu_event0_d2_cpu>, <&ppmu_event0_d3_cpu>,
				 <&ppmu_event0_d0_general>,
				 <&ppmu_event0_d1_general>,
				 <&ppmu_event0_d2_general>,
				 <&ppmu_event0_d3_general>;
		exynos,saturation-ratio = <100>;
		#interconnect-cells = <0>;

		/*
		 * memlat: DRAM floor per CPU clock (busy cycles per time,
		 * kHz; MIF kHz) for a core that waits on DRAM. The values
		 * are the stock cpufreq bus tables; each step starts halfway
		 * between two CPU OPPs, since a busy-cycle clock reads a
		 * little under the OPP it runs at.
		 */
		memlat-atlas {
			cpus = <&cpu_atlas0>, <&cpu_atlas1>,
			       <&cpu_atlas2>, <&cpu_atlas3>;
			samsung,mif-floors = <950000 543000>,
					     <1150000 635000>,
					     <1350000 836000>,
					     <1550000 1026000>,
					     <1750000 1264000>;
		};

		memlat-apollo {
			cpus = <&cpu_apollo0>, <&cpu_apollo1>,
			       <&cpu_apollo2>, <&cpu_apollo3>;
			samsung,mif-floors = <650000 543000>,
					     <850000 635000>,
					     <1050000 836000>,
					     <1250000 1026000>;
		};
	};
};

&sysmmu_disp_ro {
	status = "okay";
};

&sysmmu_disp_rw {
	status = "okay";
};

&{/timer} {
	/* S-Boot enters every CPU at EL1 and never programs CNTVOFF_EL2. */
	arm,cpu-registers-not-fw-configured;
	/* S-Boot leaves CNTFRQ_EL0 at zero, so the rate must come from the
	 * DT, as in Samsung's own exynos7420.dtsi. Without it time_init()
	 * panics: "Unable to initialise architected timer." */
	clock-frequency = <24000000>;
};

/*
 * The controller sits at the root, not under soc@0, so its device path is
 * /devices/platform/15570000.ufs. Android init names block links after
 * that path, and LineageOS expects /dev/block/platform/15570000.ufs/by-name
 * (the 3.10 name) in its fstab, ueventd.rc, init scripts and sepolicy.
 */
/delete-node/ &ufs;

/ {
	ufs: ufs@15570000 {
		compatible = "samsung,exynos7420-ufs", "samsung,exynos7-ufs";
		reg = <0 0x15570000 0 0x100>,	/* 0: HCI standard */
		      <0 0x15570100 0 0x100>,	/* 1: Vendor specific */
		      <0 0x15571000 0 0x200>,	/* 2: UNIPRO */
		      <0 0x15572000 0 0x300>;	/* 3: UFS protector */
		reg-names = "hci", "vs_hci", "unipro", "ufsp";
		interrupts = <GIC_SPI 200 IRQ_TYPE_LEVEL_HIGH>;
		clocks = <&clock_fsys1 ACLK_UFS20_LINK>,
			 <&clock_fsys1 SCLK_UFSUNIPRO20_USER>;
		clock-names = "core_clk", "sclk_unipro_main";
		freq-table-hz = <0 0>, <0 0>;
		/* S-Boot has already configured the reset and refclk pins. */
		phys = <&ufs_phy>;
		phy-names = "ufs-phy";
	};
};

/*
 * USB device mode for adb. S-Boot, unlike the uniLoader this port started
 * from, leaves the USB DRD PHY uninitialised, so the controller's first
 * endpoint command timed out ("failed to enable ep0out") and the host never
 * saw the phone. The mainline Exynos7 PHY driver now brings the PHY up.
 * The micro-USB port is USB 2.0 only.
 */
&usbdrd {
	usb@0 {
		dr_mode = "peripheral";
		maximum-speed = "high-speed";
	};
};

/*
 * The A57 watchdog resets the SoC when nothing kicks it for 15 s, so a
 * hard hang (a bus stall, all CPUs stuck) ends in a reset instead of a
 * dead phone. s3c2410_wdt.tmr_atboot starts it at probe and the watchdog
 * core kicks it until userspace opens /dev/watchdog.
 */
&watchdog {
	status = "okay";
};

/*
 * Lineage 20 keeps no fstab in its ramdisk: first-stage init reads the
 * early mounts from /firmware/android/fstab, as in the 3.10 Lineage tree's
 * exynos7420.dtsi. Without it init aborts with "failed to read default
 * fstab for first stage mount" and reboots to the bootloader.
 */
/ {
	firmware {
		android {
			compatible = "android,firmware";

			fstab {
				compatible = "android,fstab";

				system {
					compatible = "android,system";
					dev = "/dev/block/platform/15570000.ufs/by-name/SYSTEM";
					type = "ext4";
					mnt_flags = "ro,errors=panic,noload";
					fsmgr_flags = "wait";
					status = "ok";
				};

				efs {
					compatible = "android,efs";
					dev = "/dev/block/platform/15570000.ufs/by-name/EFS";
					type = "ext4";
					mnt_flags = "noatime,nosuid,nodev,noauto_da_alloc,discard,journal_checksum,data=ordered,errors=panic";
					fsmgr_flags = "wait";
					status = "ok";
				};
			};
		};
	};
};

/*
 * Trustonic t-base, loaded by S-Boot. Its notification interrupt (SSIQ)
 * is GIC SPI 214, as in the 3.10 platform header.
 */
/ {
	mobicore {
		compatible = "trustonic,mobicore";
		interrupts = <GIC_SPI 214 IRQ_TYPE_EDGE_RISING>;
	};
};

/* The TRNG, owned by the EL3 firmware and read through its SMC. */
/ {
	swd-rng {
		compatible = "samsung,exynos7420-swd-rng";
	};
};

/ {
	/* "battery" and "ac" for the ROM's thermal and health HALs. */
	sec-battery-compat {
		compatible = "samsung,sec-battery-compat";
	};
};

/ {
	/* Cooling-device names for the same HAL; see the driver. */
	sec-cooling-compat {
		compatible = "samsung,sec-cooling-compat";
	};
};

/ {
	/* mDNIe and panel nodes for Lineage's LiveDisplay HAL (inert). */
	mdnie-compat {
		compatible = "samsung,mdnie-compat";
	};
};

/*
 * Sensor hub: the SSP hub firmware runs on the Broadcom BCM4773 GNSS chip,
 * which carries the accelerometer/gyroscope (MPU6500), magnetometer
 * (YAS537), barometer (LPS25H), light/proximity (TMD4903) and grip (SX9306)
 * sensors. Board facts are from the stock rev06 DT.
 *
 * The chip sits on SPI1 as on stock: SCLK gpd6-2, MISO gpd6-4 and MOSI
 * gpd6-5 in their SPI function, CS gpd6-3 as a GPIO, mode 3. CMU_PERIC1
 * reads fine but is not registered; S-Boot leaves PCLK_SPI1 and
 * SCLK_SPI1_USER on with the user mux on CMU_TOP0, so a fixed clock stands
 * in for the PCLK and SCLK_SPI1 comes from CMU_TOP0.
 * No dmas: stock used PDMA0 requests 9 (TX) and 8 (RX), but through
 * mainline pl330 those transfers never move a byte. Without DMA the
 * controller takes at most 63 bytes per transfer, which bcm4773 keeps its
 * SSI frames to, and transfers above 32 bytes sleep on the RX FIFO
 * interrupt.
 * HOST_REQ gpa3-6 is the chip's data-ready interrupt; MCU_REQ gpf4-5 and
 * MCU_RESP gpf4-4 are the SSI handshake; nSTANDBY gpf4-7 powers the chip
 * and belongs to lhd, which loads the chip's RAM patch on every power-up.
 */
&pinctrl_alive {
	gnss_host_req: gnss-host-req-pins {
		samsung,pins = "gpa3-6";
		samsung,pin-function = <EXYNOS_PIN_FUNC_EINT>;
		samsung,pin-pud = <EXYNOS_PIN_PULL_DOWN>;
	};
};

&pinctrl_bus0 {
	/* As stock: full drive, SCLK/MOSI pulled up, MISO pulled down. */
	gnss_spi: gnss-spi-pins {
		samsung,pins = "gpd6-2", "gpd6-5";
		samsung,pin-function = <EXYNOS_PIN_FUNC_2>;
		samsung,pin-pud = <EXYNOS_PIN_PULL_UP>;
		samsung,pin-drv = <EXYNOS7_PIN_DRV_LV4>;
	};

	gnss_spi_miso: gnss-spi-miso-pins {
		samsung,pins = "gpd6-4";
		samsung,pin-function = <EXYNOS_PIN_FUNC_2>;
		samsung,pin-pud = <EXYNOS_PIN_PULL_DOWN>;
		samsung,pin-drv = <EXYNOS7_PIN_DRV_LV4>;
	};
};

&pinctrl_bus1 {
	gnss_ctrl: gnss-ctrl-pins {
		samsung,pins = "gpf4-5", "gpf4-7";
		samsung,pin-function = <EXYNOS_PIN_FUNC_OUTPUT>;
		samsung,pin-pud = <EXYNOS_PIN_PULL_NONE>;
	};

	gnss_mcu_resp: gnss-mcu-resp-pins {
		samsung,pins = "gpf4-4";
		samsung,pin-function = <EXYNOS_PIN_FUNC_INPUT>;
		samsung,pin-pud = <EXYNOS_PIN_PULL_UP>;
	};
};

/ {
	aliases {
		/* spi-s3c64xx takes its FIFO depth from the alias index. */
		spi1 = &spi_1;
	};

	clocks {
		spi1_pclk: clock-spi1-pclk {
			compatible = "fixed-clock";
			#clock-cells = <0>;
			clock-frequency = <66666667>;
			clock-output-names = "spi1_pclk";
		};
	};
};

&soc {
	spi_1: spi@14d30000 {
		compatible = "samsung,exynos7-spi";
		reg = <0x14d30000 0x100>;
		interrupts = <GIC_SPI 465 IRQ_TYPE_LEVEL_HIGH>;
		clocks = <&spi1_pclk>, <&clock_top0 CLK_SCLK_SPI1>;
		clock-names = "spi", "spi_busclk0";
		num-cs = <1>;
		cs-gpios = <&gpd6 3 GPIO_ACTIVE_LOW>;
		#address-cells = <1>;
		#size-cells = <0>;
		pinctrl-names = "default";
		pinctrl-0 = <&gnss_spi &gnss_spi_miso &gnss_host_req &gnss_ctrl
			     &gnss_mcu_resp>;

		gnss@0 {
			compatible = "brcm,bcm4773";
			reg = <0>;
			spi-max-frequency = <26000000>;
			spi-cpha;
			spi-cpol;
			interrupt-parent = <&gpa3>;
			interrupts = <6 IRQ_TYPE_LEVEL_HIGH>;
			enable-gpios = <&gpf4 7 GPIO_ACTIVE_HIGH>;
			host-req-gpios = <&gpa3 6 GPIO_ACTIVE_HIGH>;
			mcu-req-gpios = <&gpf4 5 GPIO_ACTIVE_HIGH>;
			mcu-resp-gpios = <&gpf4 4 GPIO_ACTIVE_HIGH>;

			sensorhub {
				compatible = "samsung,zeroflte-sensorhub";
				samsung,acc-position = <0>;
				samsung,mag-position = <0>;
				samsung,glass-type = <0>;
				samsung,prox-thresholds = <2000 1400>;
				/* YAS537 static matrix of the rev05-07 boards */
				samsung,mag-matrix = <10213 (-360) 154 (-206) 8673
						      (-59) (-66) (-59) 10479>;
			};
		};
	};
};

/*
 * Shannon 333 modem (CP): MIPI-LLI shared-memory IPC, SPI bootloader link.
 *
 * Hardware facts from the stock tw70-stock sources that every
 * zeroflte_eur_open revision includes:
 *   exynos7420-zerolte_modem-shannon_ds.dtsi  GPIOs, pin settings, SPI2 pins,
 *                                             LLI and M-PHY settings
 *   modem-ss333-ds-pdata.dtsi                 modem and the 18 io devices
 *   exynos7420-zero_common.dtsi               8 MiB mipi-lli-shmem carve-out
 *
 * The bootloader goes over spi-gpio on the stock SPI2 pins (gpd5-0..3):
 * the hardware SPI controllers are clocked from CMU_PERIC1, which this
 * board cannot touch. The modem driver keeps the stock name "mif_sipc5".
 */
/ {
	reserved-memory {
		/* CP IPC window; LLI remap needs size = alignment = 2^n */
		modem_ipc_mem: modem-ipc {
			compatible = "samsung,exynos7420-lli-shmem";
			size = <0x0 0x800000>;
			alignment = <0x0 0x800000>;
			no-map;
		};
	};
};

&mipi_lli {
	memory-region = <&modem_ipc_mem>;
	/* stock ss333: HS-G2 rate A, CP reference clock, no scrambler/automode */
	samsung,mphy-init-gear = <2 2 1>;
	samsung,mphy-shared-refclk;
	status = "okay";
};

&pinctrl_alive {
	/* phone_active gpa2-7, cp2ap_wakeup gpa3-1, cp_status gpa1-0 */
	modem_eint: modem-eint-pins {
		samsung,pins = "gpa2-7", "gpa3-1", "gpa1-0";
		samsung,pin-function = <EXYNOS_PIN_FUNC_EINT>;
		samsung,pin-pud = <EXYNOS_PIN_PULL_DOWN>;
		samsung,pin-drv = <EXYNOS7_PIN_DRV_LV1>;
	};

	modem_cp_dump_int: modem-cp-dump-int-pins {
		samsung,pins = "gpa1-3";
		samsung,pin-function = <EXYNOS_PIN_FUNC_EINT>;
		samsung,pin-pud = <EXYNOS_PIN_PULL_NONE>;
		samsung,pin-drv = <EXYNOS7_PIN_DRV_LV1>;
	};

	modem_ipc_int2cp: modem-ipc-int2cp-pins {
		samsung,pins = "gpa1-1";
		samsung,pin-function = <EXYNOS_PIN_FUNC_OUTPUT>;
		samsung,pin-pud = <EXYNOS_PIN_PULL_NONE>;
	};
};

&pinctrl_bus1 {
	/* cp_on, ap_dump_int, pda_active, ap2cp_status, ap2cp_wakeup, cp_reset */
	modem_ctrl_out: modem-ctrl-out-pins {
		samsung,pins = "gpf5-0", "gpf5-1", "gpf3-3", "gpf0-4", "gpf4-2",
			       "gpf1-1";
		samsung,pin-function = <EXYNOS_PIN_FUNC_OUTPUT>;
		samsung,pin-pud = <EXYNOS_PIN_PULL_NONE>;
		samsung,pin-con-pdn = <EXYNOS_PIN_PDN_PREV>;
		samsung,pin-pud-pdn = <EXYNOS_PIN_PULL_NONE>;
	};
};

&pinctrl_bus0 {
	/* stock SPI2: clk gpd5-0, cs gpd5-1, miso gpd5-2 (pull-down), mosi gpd5-3 */
	modem_spi_out: modem-spi-out-pins {
		samsung,pins = "gpd5-0", "gpd5-1", "gpd5-3";
		samsung,pin-function = <EXYNOS_PIN_FUNC_OUTPUT>;
		samsung,pin-pud = <EXYNOS_PIN_PULL_NONE>;
		samsung,pin-drv = <EXYNOS7_PIN_DRV_LV1>;
	};

	modem_spi_miso: modem-spi-miso-pins {
		samsung,pins = "gpd5-2";
		samsung,pin-function = <EXYNOS_PIN_FUNC_INPUT>;
		samsung,pin-pud = <EXYNOS_PIN_PULL_DOWN>;
	};
};

/ {
	spi-modem-boot {
		compatible = "spi-gpio";
		#address-cells = <1>;
		#size-cells = <0>;
		sck-gpios = <&gpd5 0 GPIO_ACTIVE_HIGH>;
		miso-gpios = <&gpd5 2 GPIO_ACTIVE_HIGH>;
		mosi-gpios = <&gpd5 3 GPIO_ACTIVE_HIGH>;
		cs-gpios = <&gpd5 1 GPIO_ACTIVE_LOW>;
		num-chipselects = <1>;
		pinctrl-names = "default";
		pinctrl-0 = <&modem_spi_out &modem_spi_miso>;

		modem-boot@0 {
			compatible = "samsung,ss333-spi-boot";
			reg = <0>;
			spi-max-frequency = <100000>;
		};
	};

	/*
	 * The stock node name: cbd looks for the platform device
	 * "mif_pdata" under /sys/bus/platform/drivers/mif_sipc5 while it
	 * sends the CP boot loader, and fails the boot without it.
	 */
	mif_pdata {
		compatible = "samsung,ss333-modem";
		pinctrl-names = "default";
		pinctrl-0 = <&modem_ctrl_out &modem_eint &modem_cp_dump_int
			     &modem_ipc_int2cp>;

		samsung,modem-name = "ss333";
		samsung,modem-net = <0>;
		samsung,modem-type = <15>;		/* SEC_SS333 */
		samsung,use-handover = <0>;
		samsung,ipc-version = <50>;		/* SIPC 5.0 */
		samsung,link-types = <0x408>;		/* LLI | SPI */
		samsung,link-name = "lli";
		/* DUMP/BOOT_ALIGNED, MEM_DUMP, MEM_BOOT, DPRAM_MAGIC, SBD_IPC */
		samsung,link-attrs = <0x3c9>;

		cp-on-gpios = <&gpf5 0 GPIO_ACTIVE_HIGH>;
		cp-reset-gpios = <&gpf1 1 GPIO_ACTIVE_HIGH>;
		pda-active-gpios = <&gpf3 3 GPIO_ACTIVE_HIGH>;
		phone-active-gpios = <&gpa2 7 GPIO_ACTIVE_HIGH>;
		cp-status-gpios = <&gpa1 0 GPIO_ACTIVE_HIGH>;
		ipc-int2cp-gpios = <&gpa1 1 GPIO_ACTIVE_HIGH>;
		ap-dump-int-gpios = <&gpf5 1 GPIO_ACTIVE_HIGH>;
		cp-dump-int-gpios = <&gpa1 3 GPIO_ACTIVE_HIGH>;

		link-pm {
			/* cp2ap_status is gpa1-0, the cp-status line above */
			cp2ap-wakeup-gpios = <&gpa3 1 GPIO_ACTIVE_HIGH>;
			ap2cp-wakeup-gpios = <&gpf4 2 GPIO_ACTIVE_HIGH>;
			ap2cp-status-gpios = <&gpf0 4 GPIO_ACTIVE_HIGH>;
		};

		/*
		 * format: 0 FMT, 1 RAW, 3 MULTI_RAW, 4 BOOT, 5 DUMP
		 * io-type: 0 misc, 1 net, 2 dummy
		 * attrs: 0x02 SIPC5, 0x80 SBD_IPC, 0x100 NO_LINK_HEADER,
		 *        0x200 NO_CHECK_MAXQ (enum iodev_attr_bit)
		 */
		iodevs {
			umts-ipc0 {
				iod,name = "umts_ipc0";
				iod,id = <235>;
				iod,format = <0>;
				iod,io-type = <0>;
				iod,links = <0x400>;
				iod,attrs = <0x82>;
				iod,app = "RIL";
				iod,ul-num-buffers = <16>;
				iod,ul-buffer-size = <4096>;
				iod,dl-num-buffers = <32>;
				iod,dl-buffer-size = <4096>;
			};

			umts-ipc1 {
				iod,name = "umts_ipc1";
				iod,id = <236>;
				iod,format = <0>;
				iod,io-type = <0>;
				iod,links = <0x400>;
				iod,attrs = <0x82>;
				iod,app = "RIL";
				iod,ul-num-buffers = <16>;
				iod,ul-buffer-size = <4096>;
				iod,dl-num-buffers = <32>;
				iod,dl-buffer-size = <4096>;
			};

			umts-rfs0 {
				iod,name = "umts_rfs0";
				iod,id = <245>;
				iod,format = <1>;
				iod,io-type = <0>;
				iod,links = <0x400>;
				iod,attrs = <0x82>;
				iod,app = "RFS";
				iod,ul-num-buffers = <16>;
				iod,ul-buffer-size = <2048>;
				iod,dl-num-buffers = <512>;
				iod,dl-buffer-size = <2048>;
			};

			umts-csd {
				iod,name = "umts_csd";
				iod,id = <1>;
				iod,format = <1>;
				iod,io-type = <0>;
				iod,links = <0x400>;
				iod,attrs = <0x82>;
				iod,app = "CSVT";
				iod,ul-num-buffers = <32>;
				iod,ul-buffer-size = <2048>;
				iod,dl-num-buffers = <64>;
				iod,dl-buffer-size = <2048>;
			};

			umts-router {
				iod,name = "umts_router";
				iod,id = <25>;
				iod,format = <1>;
				iod,io-type = <0>;
				iod,links = <0x400>;
				iod,attrs = <0x82>;
				iod,app = "Data Router";
				iod,ul-num-buffers = <16>;
				iod,ul-buffer-size = <2048>;
				iod,dl-num-buffers = <16>;
				iod,dl-buffer-size = <2048>;
			};

			umts-dm0 {
				iod,name = "umts_dm0";
				iod,id = <28>;
				iod,format = <1>;
				iod,io-type = <0>;
				iod,links = <0x400>;
				iod,attrs = <0x82>;
				iod,app = "DIAG";
				iod,ul-num-buffers = <16>;
				iod,ul-buffer-size = <2048>;
				iod,dl-num-buffers = <128>;
				iod,dl-buffer-size = <2048>;
			};

			ipc-loopback0 {
				iod,name = "ipc_loopback0";
				iod,id = <244>;
				iod,format = <0>;
				iod,io-type = <0>;
				iod,links = <0x400>;
				iod,attrs = <0x82>;
				iod,app = "CLD";
				iod,ul-num-buffers = <16>;
				iod,ul-buffer-size = <2048>;
				iod,dl-num-buffers = <32>;
				iod,dl-buffer-size = <2048>;
			};

			rmnet0 {
				iod,name = "rmnet0";
				iod,id = <10>;
				iod,format = <1>;
				iod,io-type = <1>;
				iod,links = <0x400>;
				iod,attrs = <0x180>;
				iod,app = "NET";
				iod,ul-num-buffers = <256>;
				iod,ul-buffer-size = <2048>;
				iod,dl-num-buffers = <512>;
				iod,dl-buffer-size = <2048>;
			};

			rmnet1 {
				iod,name = "rmnet1";
				iod,id = <11>;
				iod,format = <1>;
				iod,io-type = <1>;
				iod,links = <0x400>;
				iod,attrs = <0x180>;
				iod,app = "NET";
				iod,ul-num-buffers = <256>;
				iod,ul-buffer-size = <2048>;
				iod,dl-num-buffers = <512>;
				iod,dl-buffer-size = <2048>;
			};

			rmnet2 {
				iod,name = "rmnet2";
				iod,id = <12>;
				iod,format = <1>;
				iod,io-type = <1>;
				iod,links = <0x400>;
				iod,attrs = <0x180>;
				iod,app = "NET";
				iod,ul-num-buffers = <50>;
				iod,ul-buffer-size = <2048>;
				iod,dl-num-buffers = <100>;
				iod,dl-buffer-size = <2048>;
			};

			rmnet3 {
				iod,name = "rmnet3";
				iod,id = <13>;
				iod,format = <1>;
				iod,io-type = <1>;
				iod,links = <0x400>;
				iod,attrs = <0x180>;
				iod,app = "NET";
				iod,ul-num-buffers = <50>;
				iod,ul-buffer-size = <2048>;
				iod,dl-num-buffers = <100>;
				iod,dl-buffer-size = <2048>;
			};

			rmnet4 {
				iod,name = "rmnet4";
				iod,id = <14>;
				iod,format = <1>;
				iod,io-type = <1>;
				iod,links = <0x400>;
				iod,attrs = <0x180>;
				iod,app = "NET";
				iod,ul-num-buffers = <128>;
				iod,ul-buffer-size = <2048>;
				iod,dl-num-buffers = <256>;
				iod,dl-buffer-size = <2048>;
			};

			rmnet5 {
				iod,name = "rmnet5";
				iod,id = <15>;
				iod,format = <1>;
				iod,io-type = <1>;
				iod,links = <0x400>;
				iod,attrs = <0x180>;
				iod,app = "NET";
				iod,ul-num-buffers = <128>;
				iod,ul-buffer-size = <2048>;
				iod,dl-num-buffers = <256>;
				iod,dl-buffer-size = <2048>;
			};

			rmnet6 {
				iod,name = "rmnet6";
				iod,id = <16>;
				iod,format = <1>;
				iod,io-type = <1>;
				iod,links = <0x400>;
				iod,attrs = <0x180>;
				iod,app = "NET";
				iod,ul-num-buffers = <50>;
				iod,ul-buffer-size = <2048>;
				iod,dl-num-buffers = <100>;
				iod,dl-buffer-size = <2048>;
			};

			rmnet7 {
				iod,name = "rmnet7";
				iod,id = <17>;
				iod,format = <1>;
				iod,io-type = <1>;
				iod,links = <0x400>;
				iod,attrs = <0x180>;
				iod,app = "NET";
				iod,ul-num-buffers = <50>;
				iod,ul-buffer-size = <2048>;
				iod,dl-num-buffers = <100>;
				iod,dl-buffer-size = <2048>;
			};

			multipdp {
				iod,name = "multipdp";
				iod,id = <0>;
				iod,format = <3>;
				iod,io-type = <2>;
				iod,links = <0x400>;
				iod,attrs = <0x2>;
				iod,app = "RIL";
			};

			umts-boot0 {
				iod,name = "umts_boot0";
				iod,id = <215>;
				iod,format = <4>;
				iod,io-type = <0>;
				iod,links = <0x408>;
				/* LLI; cbd switches to SPI with IOCTL_MODEM_SET_TX_LINK */
				iod,tx-link = <10>;
				iod,attrs = <0x2>;
				iod,app = "CBD";
			};

			umts-ramdump0 {
				iod,name = "umts_ramdump0";
				iod,id = <225>;
				iod,format = <5>;
				iod,io-type = <0>;
				iod,links = <0x400>;
				iod,attrs = <0x202>;
				iod,app = "CBD";
			};
		};
	};
};

/*
 * Camera modules. Rails on the S2MPB02, with the stock names and ranges:
 * the rear module is the sensor plus the 73C2 companion, the front one the
 * S5K4E6 ("VT"). BUCK1, LDO10 and LDO16 feed other parts and stay out.
 */
&s2mpb02_regulators {
	cam_comp_core: buck2 {
		regulator-name = "VDDD_CORE_0.8V_COMP";
		regulator-min-microvolt = <650000>;
		regulator-max-microvolt = <850000>;
	};

	cam_comp_noret: ldo1 {
		regulator-name = "VDDD_NORET_0.9V_COMP";
		regulator-min-microvolt = <900000>;
		regulator-max-microvolt = <900000>;
	};

	cam_comp_core1: ldo2 {
		regulator-name = "VDDD_CORE_1.0V_COMP";
		regulator-min-microvolt = <1000000>;
		regulator-max-microvolt = <1000000>;
	};

	cam_vddd: ldo3 {
		regulator-name = "VDDD_1.2V_CAM";
		regulator-min-microvolt = <1000000>;
		regulator-max-microvolt = <1200000>;
	};

	cam_comp_ret: ldo4 {
		regulator-name = "VDDD_RET_1.0V_COMP";
		regulator-min-microvolt = <700000>;
		regulator-max-microvolt = <1000000>;
	};

	vt_vddd: ldo5 {
		regulator-name = "VDDD_1.2V_VT";
		regulator-min-microvolt = <1200000>;
		regulator-max-microvolt = <1200000>;
	};

	vt_vddio: ldo6 {
		regulator-name = "VDDIO_1.8V_VT";
		regulator-min-microvolt = <1800000>;
		regulator-max-microvolt = <1800000>;
	};

	cam_vddio: ldo7 {
		regulator-name = "VDDIO_1.8V_CAM";
		regulator-min-microvolt = <1800000>;
		regulator-max-microvolt = <1800000>;
	};

	cam_comp_vddio: ldo8 {
		regulator-name = "VDDIO_1.8V_COMP";
		regulator-min-microvolt = <1800000>;
		regulator-max-microvolt = <1800000>;
	};

	cam_comp_vdda: ldo9 {
		regulator-name = "VDDA_1.8V_COMP";
		regulator-min-microvolt = <1800000>;
		regulator-max-microvolt = <1800000>;
	};

	cam_vdda: ldo11 {
		regulator-name = "VDDA_2.9V_CAM";
		regulator-min-microvolt = <2800000>;
		regulator-max-microvolt = <2950000>;
	};

	cam_vddaf: ldo12 {
		regulator-name = "VDDAF_2.8V_CAM";
		regulator-min-microvolt = <2800000>;
		regulator-max-microvolt = <2800000>;
	};

	vt_vdda: ldo13 {
		regulator-name = "VDDA_2.9V_VT";
		regulator-min-microvolt = <2900000>;
		regulator-max-microvolt = <2900000>;
	};

	cam_ois_vm: ldo14 {
		regulator-name = "OIS_VM_2.8V";
		regulator-min-microvolt = <2800000>;
		regulator-max-microvolt = <2800000>;
	};

	cam_ois_vdd: ldo15 {
		regulator-name = "OIS_VDD_2.8V";
		regulator-min-microvolt = <2800000>;
		regulator-max-microvolt = <2800000>;
	};
};

&pinctrl_bus0 {
	/* MCLK0 rear sensor, MCLK1 companion, MCLK2 front sensor */
	cam_mclk01_off: cam-mclk01-off-pins {
		samsung,pins = "gpd7-0", "gpd7-1";
		samsung,pin-function = <EXYNOS_PIN_FUNC_INPUT>;
		samsung,pin-pud = <EXYNOS_PIN_PULL_DOWN>;
	};

	cam_mclk2_off: cam-mclk2-off-pins {
		samsung,pins = "gpd7-2";
		samsung,pin-function = <EXYNOS_PIN_FUNC_INPUT>;
		samsung,pin-pud = <EXYNOS_PIN_PULL_DOWN>;
	};

	cam_mclk01_on: cam-mclk01-on-pins {
		samsung,pins = "gpd7-0", "gpd7-1";
		samsung,pin-function = <EXYNOS_PIN_FUNC_2>;
		samsung,pin-pud = <EXYNOS_PIN_PULL_NONE>;
	};

	cam_mclk2_on: cam-mclk2-on-pins {
		samsung,pins = "gpd7-2";
		samsung,pin-function = <EXYNOS_PIN_FUNC_2>;
		samsung,pin-pud = <EXYNOS_PIN_PULL_NONE>;
	};
};

/ {
	/*
	 * The camera I2C pins belong to the ISP's own I2C blocks, which its
	 * firmware drives on stock. The AP bit-bangs them, as stock already
	 * does on the rear bus for the companion.
	 */
	cam_i2c0: i2c-cam0 {
		compatible = "i2c-gpio";
		sda-gpios = <&gpc2 0 (GPIO_ACTIVE_HIGH | GPIO_OPEN_DRAIN)>;
		scl-gpios = <&gpc2 1 (GPIO_ACTIVE_HIGH | GPIO_OPEN_DRAIN)>;
		i2c-gpio,delay-us = <2>;
		#address-cells = <1>;
		#size-cells = <0>;
	};

	cam_i2c1: i2c-cam1 {
		compatible = "i2c-gpio";
		sda-gpios = <&gpc2 2 (GPIO_ACTIVE_HIGH | GPIO_OPEN_DRAIN)>;
		scl-gpios = <&gpc2 3 (GPIO_ACTIVE_HIGH | GPIO_OPEN_DRAIN)>;
		i2c-gpio,delay-us = <2>;
		#address-cells = <1>;
		#size-cells = <0>;
	};
};

/*
 * Rear module companion (73C2). Registers and firmware go over the pins of
 * the ISP's SPI1 (spi_7 at 0x143A0000 on stock), whose controller is in
 * CMU_CAM1, which has no driver here: SCLK gpc3-4, CS gpc3-5, MISO gpc3-6,
 * MOSI gpc3-7, bit-banged by spi-exynos-gpio. The chip answers on
 * the rear camera I2C bus at 0x3d. Its node carries the power of the whole
 * rear module, in the stock order: sensor rails, then its own, then MCLK,
 * its reset (gpc0-7) and the sensor's (gpc0-5).
 */
&pinctrl_bus0 {
	cam_spi_pins: cam-spi-pins {
		samsung,pins = "gpc3-4", "gpc3-5", "gpc3-6", "gpc3-7";
		samsung,pin-pud = <EXYNOS_PIN_PULL_NONE>;
		samsung,pin-drv = <EXYNOS7_PIN_DRV_LV1>;
	};
};

/ {
	spi-cam {
		compatible = "samsung,exynos-spi-gpio";
		#address-cells = <1>;
		#size-cells = <0>;
		sck-gpios = <&gpc3 4 GPIO_ACTIVE_HIGH>;
		miso-gpios = <&gpc3 6 GPIO_ACTIVE_HIGH>;
		mosi-gpios = <&gpc3 7 GPIO_ACTIVE_HIGH>;
		cs-gpios = <&gpc3 5 GPIO_ACTIVE_LOW>;
		pinctrl-names = "default";
		pinctrl-0 = <&cam_spi_pins>;

		cam_comp_spi: companion@0 {
			compatible = "samsung,s5c73c2-spi";
			reg = <0>;
			spi-max-frequency = <50000000>;
		};
	};
};

&cam_i2c0 {
	companion@3d {
		compatible = "samsung,s5c73c2";
		reg = <0x3d>;
		samsung,spi-device = <&cam_comp_spi>;
		vddaf-supply = <&cam_vddaf>;
		vdda-supply = <&cam_vdda>;
		ois-vdd-supply = <&cam_ois_vdd>;
		ois-vm-supply = <&cam_ois_vm>;
		vddio-supply = <&cam_vddio>;
		vddd-supply = <&cam_vddd>;
		comp-ret-supply = <&cam_comp_ret>;
		comp-vddio-supply = <&cam_comp_vddio>;
		comp-vdda-supply = <&cam_comp_vdda>;
		comp-vddd-supply = <&cam_comp_core1>;
		comp-noret-supply = <&cam_comp_noret>;
		comp-core-supply = <&cam_comp_core>;
		clocks = <&clock_top0 CLK_SCLK_ISP_SENSOR1>,
			 <&clock_top0 CLK_SCLK_ISP_SENSOR0>;
		clock-names = "mclk", "sensor-mclk";
		assigned-clocks = <&clock_top0 CLK_MOUT_SCLK_ISP_SENSOR1>,
				  <&clock_top0 CLK_MOUT_SCLK_ISP_SENSOR0>;
		assigned-clock-parents = <&fin_pll>, <&fin_pll>;
		pinctrl-names = "default", "active";
		pinctrl-0 = <&cam_mclk01_off>;
		pinctrl-1 = <&cam_mclk01_on>;
		reset-gpios = <&gpc0 7 GPIO_ACTIVE_LOW>;
		sensor-reset-gpios = <&gpc0 5 GPIO_ACTIVE_LOW>;
	};
};
